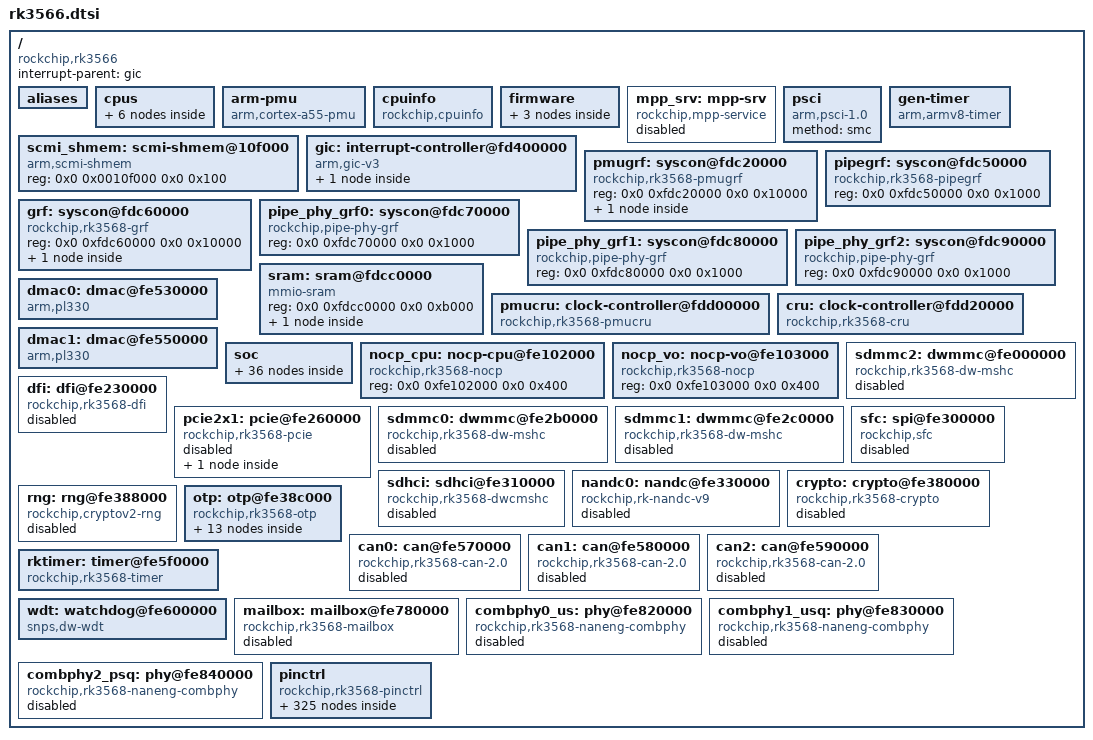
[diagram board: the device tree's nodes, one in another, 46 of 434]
/**
 * Copyright (c) 2019 PT Switch.
 * All rights reserved.
 *
 * This program is free software; you can redistribute it and/or modify
 * it under the terms of the GNU General Public License as published by
 * the Free Software Foundation; either version 2, or (at your option)
 * any later version.
 *
 * This program is distributed in the hope that it will be useful,
 * but WITHOUT ANY WARRANTY; without even the implied warranty of
 * MERCHANTABILITY or FITNESS FOR A PARTICULAR PURPOSE.  See the
 * GNU General Public License for more details.
 *
 * You should have received a copy of the GNU General Public License
 * along with this program; if not, write to the Free Software
 * Foundation, Inc., 675 Mass Ave, Cambridge, MA 02139, USA.
 *
 * @file rk3566.dtsi
 * @author
 * @brief RK3566 SOC device tree
 */

#include <dt-bindings/clock/rk3568-cru.h>
#include <dt-bindings/interrupt-controller/arm-gic.h>
#include <dt-bindings/interrupt-controller/irq.h>
#include <dt-bindings/pinctrl/rockchip.h>
#include <dt-bindings/phy/phy.h>

/ {
	compatible = "rockchip,rk3566";
	interrupt-parent = <&gic>;
	#address-cells = <2>;
	#size-cells = <2>;

    aliases {  };

	cpus {
		#address-cells = <2>;
		#size-cells = <0>;

		cpu@0 {
			device_type = "cpu";
			compatible = "arm,cortex-a55";
			reg = <0>;
			enable-method = "psci";
			clocks = <&scmi_clk 0>;
			cpu-idle-states = <&CPU_SLEEP>;
			#cooling-cells = <2>;
		};

		cpu@1 {
			device_type = "cpu";
			compatible = "arm,cortex-a55";
			reg = <1>;
			enable-method = "psci";
			clocks = <&scmi_clk 0>;
			cpu-idle-states = <&CPU_SLEEP>;
		};

		cpu@2 {
			device_type = "cpu";
			compatible = "arm,cortex-a55";
			reg = <2>;
			enable-method = "psci";
			clocks = <&scmi_clk 0>;
			cpu-idle-states = <&CPU_SLEEP>;
		};

		cpu@3 {
			device_type = "cpu";
			compatible = "arm,cortex-a55";
			reg = <3>;
			enable-method = "psci";
			clocks = <&scmi_clk 0>;
			cpu-idle-states = <&CPU_SLEEP>;
		};

		idle-states {
			entry-method = "psci";
			CPU_SLEEP: cpu-sleep {
				compatible = "arm,idle-state";
				local-timer-stop;
				arm,psci-suspend-param = <0x0010000>;
				entry-latency-us = <100>;
				exit-latency-us = <120>;
				min-residency-us = <1000>;
			};
		};
	};

	arm-pmu {
		compatible = "arm,cortex-a55-pmu", "arm,armv8-pmuv3";
		interrupts = <GIC_SPI 228 IRQ_TYPE_LEVEL_HIGH>,
			     <GIC_SPI 229 IRQ_TYPE_LEVEL_HIGH>,
			     <GIC_SPI 230 IRQ_TYPE_LEVEL_HIGH>,
			     <GIC_SPI 231 IRQ_TYPE_LEVEL_HIGH>;
		// interrupt-affinity = <&cpu0>, <&cpu1>, <&cpu2>, <&cpu3>;
	};

	cpuinfo {
		compatible = "rockchip,cpuinfo";
		nvmem-cells = <&otp_id>, <&otp_cpu_version>, <&cpu_code>, <&performance>;
		nvmem-cell-names = "id", "cpu-version", "cpu-code", "performance";
	};

	firmware {
		scmi: scmi {
			compatible = "arm,scmi-smc";
			shmem = <&scmi_shmem>;
			arm,smc-id = <0x82000010>;
			#address-cells = <1>;
			#size-cells = <0>;

			scmi_clk: protocol@14 {
				reg = <0x14>;
				#clock-cells = <1>;

				rockchip,clk-init = <1104000000>;
			};
		};

		sdei: sdei {
			compatible = "arm,sdei-1.0";
			method = "smc";
		};
	};

	mpp_srv: mpp-srv {
		compatible = "rockchip,mpp-service";
		rockchip,taskqueue-count = <6>;
		rockchip,resetgroup-count = <6>;
		status = "disabled";
	};

	psci {
		compatible = "arm,psci-1.0";
		method = "smc";
	};

	gen-timer {
		compatible = "arm,armv8-timer";
		interrupts = <GIC_PPI 13 (GIC_CPU_MASK_SIMPLE(4) | IRQ_TYPE_LEVEL_HIGH)>,
			     <GIC_PPI 14 (GIC_CPU_MASK_SIMPLE(4) | IRQ_TYPE_LEVEL_HIGH)>,
			     <GIC_PPI 11 (GIC_CPU_MASK_SIMPLE(4) | IRQ_TYPE_LEVEL_HIGH)>,
			     <GIC_PPI 10 (GIC_CPU_MASK_SIMPLE(4) | IRQ_TYPE_LEVEL_HIGH)>;
		arm,no-tick-in-suspend;
	};

	scmi_shmem: scmi-shmem@10f000 {
		compatible = "arm,scmi-shmem";
		reg = <0x0 0x0010f000 0x0 0x100>;
	};

	gic: interrupt-controller@fd400000 {
		compatible = "arm,gic-v3";
		#interrupt-cells = <3>;
		#address-cells = <2>;
		#size-cells = <2>;
		ranges;
		interrupt-controller;

		reg = <0x0 0xfd400000 0 0x10000>, /* GICD */
		      <0x0 0xfd460000 0 0xc0000>; /* GICR */
		interrupts = <GIC_PPI 9 IRQ_TYPE_LEVEL_HIGH>;
		its: interrupt-controller@fd440000 {
			compatible = "arm,gic-v3-its";
			msi-controller;
			#msi-cells = <1>;
			reg = <0x0 0xfd440000 0x0 0x20000>;
		};
	};

	pmugrf: syscon@fdc20000 {
		compatible = "rockchip,rk3568-pmugrf", "syscon", "simple-mfd";
		reg = <0x0 0xfdc20000 0x0 0x10000>;

		pmu_io_domains: io-domains {
			compatible = "rockchip,rk3568-pmu-io-voltage-domain";
			status = "disabled";
		};

        #if 0
		reboot_mode: reboot-mode {
			compatible = "syscon-reboot-mode";
			offset = <0x200>;
			mode-bootloader = <BOOT_BL_DOWNLOAD>;
			mode-charge = <BOOT_CHARGING>;
			mode-fastboot = <BOOT_FASTBOOT>;
			mode-loader = <BOOT_BL_DOWNLOAD>;
			mode-normal = <BOOT_NORMAL>;
			mode-recovery = <BOOT_RECOVERY>;
			mode-ums = <BOOT_UMS>;
			mode-panic = <BOOT_PANIC>;
			mode-watchdog = <BOOT_WATCHDOG>;
		};
        #endif
	};

	pipegrf: syscon@fdc50000 {
		compatible = "rockchip,rk3568-pipegrf", "syscon";
		reg = <0x0 0xfdc50000 0x0 0x1000>;
	};

	grf: syscon@fdc60000 {
		compatible = "rockchip,rk3568-grf", "syscon", "simple-mfd";
		reg = <0x0 0xfdc60000 0x0 0x10000>;

		io_domains: io-domains {
			compatible = "rockchip,rk3568-io-voltage-domain";
			status = "disabled";
		};
	};

	pipe_phy_grf0: syscon@fdc70000 {
		compatible = "rockchip,pipe-phy-grf", "syscon";
		reg = <0x0 0xfdc70000 0x0 0x1000>;
	};

	pipe_phy_grf1: syscon@fdc80000 {
		compatible = "rockchip,pipe-phy-grf", "syscon";
		reg = <0x0 0xfdc80000 0x0 0x1000>;
	};

	pipe_phy_grf2: syscon@fdc90000 {
		compatible = "rockchip,pipe-phy-grf", "syscon";
		reg = <0x0 0xfdc90000 0x0 0x1000>;
	};

	sram: sram@fdcc0000 {
		compatible = "mmio-sram";
		reg = <0x0 0xfdcc0000 0x0 0xb000>;

		#address-cells = <1>;
		#size-cells = <1>;
		ranges = <0x0 0x0 0xfdcc0000 0xb000>;

		/* start address and size should be 4k algin */
		rkvdec_sram: rkvdec-sram@0 {
			reg = <0x0 0xb000>;
		};
	};

	pmucru: clock-controller@fdd00000 {
		compatible = "rockchip,rk3568-pmucru";
		reg = <0x0 0xfdd00000 0x0 0x1000>;
		rockchip,grf = <&grf>;
		rockchip,pmugrf = <&pmugrf>;
		#clock-cells = <1>;
		#reset-cells = <1>;

		assigned-clocks = <&pmucru SCLK_32K_IOE>;
		assigned-clock-parents = <&pmucru CLK_RTC_32K>;
	};

	cru: clock-controller@fdd20000 {
		compatible = "rockchip,rk3568-cru";
		reg = <0x0 0xfdd20000 0x0 0x1000>;
		rockchip,grf = <&grf>;
		#clock-cells = <1>;
		#reset-cells = <1>;

		assigned-clocks =
			<&pmucru CLK_RTC_32K>, <&cru ACLK_RKVDEC_PRE>,
			<&cru CLK_RKVDEC_CORE>, <&pmucru PLL_PPLL>,
			<&pmucru PCLK_PMU>, <&cru PLL_CPLL>,
			<&cru CPLL_500M>, <&cru CPLL_333M>,
			<&cru CPLL_250M>, <&cru CPLL_125M>,
			<&cru CPLL_100M>, <&cru CPLL_62P5M>,
			<&cru CPLL_50M>, <&cru CPLL_25M>,
			<&cru PLL_GPLL>,
			<&cru ACLK_BUS>, <&cru PCLK_BUS>,
			<&cru ACLK_TOP_HIGH>, <&cru ACLK_TOP_LOW>,
			<&cru HCLK_TOP>, <&cru PCLK_TOP>,
			<&cru ACLK_PERIMID>, <&cru HCLK_PERIMID>,
			<&cru PLL_NPLL>, <&cru ACLK_PIPE>,
			<&cru PCLK_PIPE>, <&cru CLK_I2S0_8CH_TX_SRC>,
			<&cru CLK_I2S0_8CH_RX_SRC>, <&cru CLK_I2S1_8CH_TX_SRC>,
			<&cru CLK_I2S1_8CH_RX_SRC>, <&cru CLK_I2S2_2CH_SRC>,
			<&cru CLK_I2S2_2CH_SRC>, <&cru CLK_I2S3_2CH_RX_SRC>,
			<&cru CLK_I2S3_2CH_TX_SRC>, <&cru MCLK_SPDIF_8CH_SRC>,
			<&cru ACLK_VOP>;
		assigned-clock-rates =
			<32768>, <300000000>,
			<300000000>, <200000000>,
			<100000000>, <1000000000>,
			<500000000>, <333000000>,
			<250000000>, <125000000>,
			<100000000>, <62500000>,
			<50000000>, <25000000>,
			<1188000000>,
			<150000000>, <100000000>,
			<500000000>, <400000000>,
			<150000000>, <100000000>,
			<300000000>, <150000000>,
			<1200000000>, <400000000>,
			<100000000>, <1188000000>,
			<1188000000>, <1188000000>,
			<1188000000>, <1188000000>,
			<1188000000>, <1188000000>,
			<1188000000>, <1188000000>,
			<500000000>;
		assigned-clock-parents =
			<&pmucru CLK_RTC32K_FRAC>, <&cru PLL_GPLL>,
			<&cru PLL_GPLL>;
	};

	dmac0: dmac@fe530000 {
		compatible = "arm,pl330", "arm,primecell";
		reg = <0x0 0xfe530000 0x0 0x4000>;
		interrupts = <GIC_SPI 14 IRQ_TYPE_LEVEL_HIGH>,
			     <GIC_SPI 13 IRQ_TYPE_LEVEL_HIGH>;
		clocks = <&cru ACLK_BUS>;
		clock-names = "apb_pclk";
		#dma-cells = <1>;
		arm,pl330-periph-burst;
	};

	dmac1: dmac@fe550000 {
		compatible = "arm,pl330", "arm,primecell";
		reg = <0x0 0xfe550000 0x0 0x4000>;
		interrupts = <GIC_SPI 16 IRQ_TYPE_LEVEL_HIGH>,
			     <GIC_SPI 15 IRQ_TYPE_LEVEL_HIGH>;
		clocks = <&cru ACLK_BUS>;
		clock-names = "apb_pclk";
		#dma-cells = <1>;
		arm,pl330-periph-burst;
	};

    soc: soc {
        i2c0: i2c@fdd40000 {
            compatible = "rockchip,rk3399-i2c";
            reg = <0x0 0xfdd40000 0x0 0x1000>;
            clocks = <&pmucru CLK_I2C0>, <&pmucru PCLK_I2C0>;
            clock-names = "i2c", "pclk";
            interrupts = <GIC_SPI 46 IRQ_TYPE_LEVEL_HIGH>;
            pinctrl-names = "default";
            pinctrl-0 = <&i2c0_xfer>;
            #address-cells = <1>;
            #size-cells = <0>;
            status = "disabled";
        };

        i2c1: i2c@fe5a0000 {
            compatible = "rockchip,rk3399-i2c";
            reg = <0x0 0xfe5a0000 0x0 0x1000>;
            clocks = <&cru CLK_I2C1>, <&cru PCLK_I2C1>;
            clock-names = "i2c", "pclk";
            interrupts = <GIC_SPI 47 IRQ_TYPE_LEVEL_HIGH>;
            pinctrl-names = "default";
            pinctrl-0 = <&i2c1_xfer>;
            #address-cells = <1>;
            #size-cells = <0>;
            status = "disabled";
        };

        i2c2: i2c@fe5b0000 {
            compatible = "rockchip,rk3399-i2c";
            reg = <0x0 0xfe5b0000 0x0 0x1000>;
            clocks = <&cru CLK_I2C2>, <&cru PCLK_I2C2>;
            clock-names = "i2c", "pclk";
            interrupts = <GIC_SPI 48 IRQ_TYPE_LEVEL_HIGH>;
            pinctrl-names = "default";
            pinctrl-0 = <&i2c2m0_xfer>;
            #address-cells = <1>;
            #size-cells = <0>;
            status = "disabled";
        };

        i2c3: i2c@fe5c0000 {
            compatible = "rockchip,rk3399-i2c";
            reg = <0x0 0xfe5c0000 0x0 0x1000>;
            clocks = <&cru CLK_I2C3>, <&cru PCLK_I2C3>;
            clock-names = "i2c", "pclk";
            interrupts = <GIC_SPI 49 IRQ_TYPE_LEVEL_HIGH>;
            pinctrl-names = "default";
            pinctrl-0 = <&i2c3m0_xfer>;
            #address-cells = <1>;
            #size-cells = <0>;
            status = "disabled";
        };

        i2c4: i2c@fe5d0000 {
            compatible = "rockchip,rk3399-i2c";
            reg = <0x0 0xfe5d0000 0x0 0x1000>;
            clocks = <&cru CLK_I2C4>, <&cru PCLK_I2C4>;
            clock-names = "i2c", "pclk";
            interrupts = <GIC_SPI 50 IRQ_TYPE_LEVEL_HIGH>;
            pinctrl-names = "default";
            pinctrl-0 = <&i2c4m0_xfer>;
            #address-cells = <1>;
            #size-cells = <0>;
            status = "disabled";
        };

        i2c5: i2c@fe5e0000 {
            compatible = "rockchip,rk3399-i2c";
            reg = <0x0 0xfe5e0000 0x0 0x1000>;
            clocks = <&cru CLK_I2C5>, <&cru PCLK_I2C5>;
            clock-names = "i2c", "pclk";
            interrupts = <GIC_SPI 51 IRQ_TYPE_LEVEL_HIGH>;
            pinctrl-names = "default";
            pinctrl-0 = <&i2c5m0_xfer>;
            #address-cells = <1>;
            #size-cells = <0>;
            status = "disabled";
        };
        /* fdd50000 */
        SERIAL0: uart0 {
            compatible = "rockchip,rk3568-uart", "snps,dw-apb-uart";
            reg = <0x0 0xfdd50000 0x0 0x100>;
            interrupts = <GIC_SPI 116 IRQ_TYPE_LEVEL_HIGH>;
            clocks = <&pmucru SCLK_UART0>, <&pmucru PCLK_UART0>;
            clock-names = "baudclk", "apb_pclk";
            reg-shift = <2>;
            reg-io-width = <4>;
            dmas = <&dmac0 0>, <&dmac0 1>;
            pinctrl-names = "default";
            pinctrl-0 = <&uart0_xfer>;
            status = "disabled";
        };
        /* fe650000 */
        SERIAL1: uart1 {
            compatible = "rockchip,rk3568-uart", "snps,dw-apb-uart";
            reg = <0x0 0xfe650000 0x0 0x100>;
            interrupts = <GIC_SPI 117 IRQ_TYPE_LEVEL_HIGH>;
            clocks = <&cru SCLK_UART1>, <&cru PCLK_UART1>;
            clock-names = "baudclk", "apb_pclk";
            reg-shift = <2>;
            reg-io-width = <4>;
            dmas = <&dmac0 2>, <&dmac0 3>;
            pinctrl-names = "default";
            pinctrl-0 = <&uart1m0_xfer>;
            status = "disabled";
        };

        /* fe660000 */
        SERIAL2: uart2 {
            compatible = "snps,dw-apb-uart";
            reg = <0x0 0xfe660000 0x0 0x100>;
            interrupts = <GIC_SPI 118 IRQ_TYPE_LEVEL_HIGH>;
            clocks = <&cru SCLK_UART2>, <&cru PCLK_UART2>;
            clock-names = "baudclk", "apb_pclk";
            reg-shift = <2>;
            reg-io-width = <4>;
            dmas = <&dmac0 4>, <&dmac0 5>;
            pinctrl-names = "debug-serial";
            pinctrl-0 = <&uart2m0_xfer>;
            status = "okay";
        };
        /* fe670000 */
        SERIAL3: uart3 {
            compatible = "rockchip,rk3568-uart", "snps,dw-apb-uart";
            reg = <0x0 0xfe670000 0x0 0x100>;
            interrupts = <GIC_SPI 119 IRQ_TYPE_LEVEL_HIGH>;
            clocks = <&cru SCLK_UART3>, <&cru PCLK_UART3>;
            clock-names = "baudclk", "apb_pclk";
            reg-shift = <2>;
            reg-io-width = <4>;
            dmas = <&dmac0 6>, <&dmac0 7>;
            pinctrl-names = "default";
            pinctrl-0 = <&uart3m0_xfer>;
            status = "disabled";
        };
        /* fe680000 */
        SERIAL4: uart4 {
            compatible = "rockchip,rk3568-uart", "snps,dw-apb-uart";
            reg = <0x0 0xfe680000 0x0 0x100>;
            interrupts = <GIC_SPI 120 IRQ_TYPE_LEVEL_HIGH>;
            clocks = <&cru SCLK_UART4>, <&cru PCLK_UART4>;
            clock-names = "baudclk", "apb_pclk";
            reg-shift = <2>;
            reg-io-width = <4>;
            dmas = <&dmac0 8>, <&dmac0 9>;
            pinctrl-names = "default";
            pinctrl-0 = <&uart4m0_xfer>;
            status = "disabled";
        };
        /* fe690000 */
        SERIAL5: uart5 {
            compatible = "rockchip,rk3568-uart", "snps,dw-apb-uart";
            reg = <0x0 0xfe690000 0x0 0x100>;
            interrupts = <GIC_SPI 121 IRQ_TYPE_LEVEL_HIGH>;
            clocks = <&cru SCLK_UART5>, <&cru PCLK_UART5>;
            clock-names = "baudclk", "apb_pclk";
            reg-shift = <2>;
            reg-io-width = <4>;
            dmas = <&dmac0 10>, <&dmac0 11>;
            pinctrl-names = "default";
            pinctrl-0 = <&uart5m0_xfer>;
            status = "disabled";
        };
        /* fe6a0000 */
        SERIAL6: uart6 {
            compatible = "rockchip,rk3568-uart", "snps,dw-apb-uart";
            reg = <0x0 0xfe6a0000 0x0 0x100>;
            interrupts = <GIC_SPI 122 IRQ_TYPE_LEVEL_HIGH>;
            clocks = <&cru SCLK_UART6>, <&cru PCLK_UART6>;
            clock-names = "baudclk", "apb_pclk";
            reg-shift = <2>;
            reg-io-width = <4>;
            dmas = <&dmac0 12>, <&dmac0 13>;
            pinctrl-names = "default";
            pinctrl-0 = <&uart6m0_xfer>;
            status = "disabled";
        };
        /* fe6b0000 */
        SERIAL7: uart7 {
            compatible = "rockchip,rk3568-uart", "snps,dw-apb-uart";
            reg = <0x0 0xfe6b0000 0x0 0x100>;
            interrupts = <GIC_SPI 123 IRQ_TYPE_LEVEL_HIGH>;
            clocks = <&cru SCLK_UART7>, <&cru PCLK_UART7>;
            clock-names = "baudclk", "apb_pclk";
            reg-shift = <2>;
            reg-io-width = <4>;
            dmas = <&dmac0 14>, <&dmac0 15>;
            pinctrl-names = "default";
            pinctrl-0 = <&uart7m0_xfer>;
            status = "disabled";
        };
        /* fe6c0000 */
        SERIAL8: uart8 {
            compatible = "rockchip,rk3568-uart", "snps,dw-apb-uart";
            reg = <0x0 0xfe6c0000 0x0 0x100>;
            interrupts = <GIC_SPI 124 IRQ_TYPE_LEVEL_HIGH>;
            clocks = <&cru SCLK_UART8>, <&cru PCLK_UART8>;
            clock-names = "baudclk", "apb_pclk";
            reg-shift = <2>;
            reg-io-width = <4>;
            dmas = <&dmac0 16>, <&dmac0 17>;
            pinctrl-names = "default";
            pinctrl-0 = <&uart8m0_xfer>;
            status = "disabled";
        };
        /* fe6d0000 */
        SERIAL9: uart9 {
            compatible = "rockchip,rk3568-uart", "snps,dw-apb-uart";
            reg = <0x0 0xfe6d0000 0x0 0x100>;
            interrupts = <GIC_SPI 125 IRQ_TYPE_LEVEL_HIGH>;
            clocks = <&cru SCLK_UART9>, <&cru PCLK_UART9>;
            clock-names = "baudclk", "apb_pclk";
            reg-shift = <2>;
            reg-io-width = <4>;
            dmas = <&dmac0 18>, <&dmac0 19>;
            pinctrl-names = "default";
            pinctrl-0 = <&uart9m0_xfer>;
            status = "disabled";
        };

        spi0: spi@fe610000 {
            compatible = "rockchip,rk3066-spi";
            reg = <0x0 0xfe610000 0x0 0x1000>;
            interrupts = <GIC_SPI 103 IRQ_TYPE_LEVEL_HIGH>;
            #address-cells = <1>;
            #size-cells = <0>;
            clocks = <&cru CLK_SPI0>, <&cru PCLK_SPI0>;
            clock-names = "spiclk", "apb_pclk";
            dmas = <&dmac0 20>, <&dmac0 21>;
            dma-names = "tx", "rx";
            pinctrl-names = "default", "high_speed";
            pinctrl-0 = <&spi0m0_cs0 &spi0m0_cs1 &spi0m0_pins>;
            pinctrl-1 = <&spi0m0_cs0 &spi0m0_cs1 &spi0m0_pins_hs>;
            num-cs = <2>;
            status = "disabled";
        };

        spi1: spi@fe620000 {
            compatible = "rockchip,rk3066-spi";
            reg = <0x0 0xfe620000 0x0 0x1000>;
            interrupts = <GIC_SPI 104 IRQ_TYPE_LEVEL_HIGH>;
            #address-cells = <1>;
            #size-cells = <0>;
            clocks = <&cru CLK_SPI1>, <&cru PCLK_SPI1>;
            clock-names = "spiclk", "apb_pclk";
            dmas = <&dmac0 22>, <&dmac0 23>;
            dma-names = "tx", "rx";
            pinctrl-names = "default", "high_speed";
            pinctrl-0 = <&spi1m0_cs0 &spi1m0_cs1 &spi1m0_pins>;
            pinctrl-1 = <&spi1m0_cs0 &spi1m0_cs1 &spi1m0_pins_hs>;
            num-cs = <2>;
            status = "disabled";
        };

        spi2: spi@fe630000 {
            compatible = "rockchip,rk3066-spi";
            reg = <0x0 0xfe630000 0x0 0x1000>;
            interrupts = <GIC_SPI 105 IRQ_TYPE_LEVEL_HIGH>;
            #address-cells = <1>;
            #size-cells = <0>;
            clocks = <&cru CLK_SPI2>, <&cru PCLK_SPI2>;
            clock-names = "spiclk", "apb_pclk";
            dmas = <&dmac0 24>, <&dmac0 25>;
            dma-names = "tx", "rx";
            pinctrl-names = "default", "high_speed";
            pinctrl-0 = <&spi2m0_cs0 &spi2m0_cs1 &spi2m0_pins>;
            pinctrl-1 = <&spi2m0_cs0 &spi2m0_cs1 &spi2m0_pins_hs>;
            num-cs = <2>;
            status = "disabled";
        };

        spi3: spi@fe640000 {
            compatible = "rockchip,rk3066-spi";
            reg = <0x0 0xfe640000 0x0 0x1000>;
            interrupts = <GIC_SPI 106 IRQ_TYPE_LEVEL_HIGH>;
            #address-cells = <1>;
            #size-cells = <0>;
            clocks = <&cru CLK_SPI3>, <&cru PCLK_SPI3>;
            clock-names = "spiclk", "apb_pclk";
            dmas = <&dmac0 26>, <&dmac0 27>;
            dma-names = "tx", "rx";
            pinctrl-names = "default", "high_speed";
            pinctrl-0 = <&spi3m0_cs0 &spi3m0_cs1 &spi3m0_pins>;
            pinctrl-1 = <&spi3m0_cs0 &spi3m0_cs1 &spi3m0_pins_hs>;
            num-cs = <2>;
            status = "disabled";
        };

        pwm0: pwm@fdd70000 {
            compatible = "rockchip,rk3568-pwm", "rockchip,rk3328-pwm";
            reg = <0x0 0xfdd70000 0x0 0x10>;
            #pwm-cells = <3>;
            pinctrl-names = "active";
            pinctrl-0 = <&pwm0m0_pins>;
            clocks = <&pmucru CLK_PWM0>, <&pmucru PCLK_PWM0>;
            clock-names = "pwm", "pclk";
            status = "disabled";
        };

        pwm1: pwm@fdd70010 {
            compatible = "rockchip,rk3568-pwm", "rockchip,rk3328-pwm";
            reg = <0x0 0xfdd70010 0x0 0x10>;
            #pwm-cells = <3>;
            pinctrl-names = "active";
            pinctrl-0 = <&pwm1m0_pins>;
            clocks = <&pmucru CLK_PWM0>, <&pmucru PCLK_PWM0>;
            clock-names = "pwm", "pclk";
            status = "disabled";
        };

        pwm2: pwm@fdd70020 {
            compatible = "rockchip,rk3568-pwm", "rockchip,rk3328-pwm";
            reg = <0x0 0xfdd70020 0x0 0x10>;
            #pwm-cells = <3>;
            pinctrl-names = "active";
            pinctrl-0 = <&pwm2m0_pins>;
            clocks = <&pmucru CLK_PWM0>, <&pmucru PCLK_PWM0>;
            clock-names = "pwm", "pclk";
            status = "disabled";
        };

        pwm3: pwm@fdd70030 {
            compatible = "rockchip,rk3568-pwm", "rockchip,rk3328-pwm";
            reg = <0x0 0xfdd70030 0x0 0x10>;
            interrupts = <GIC_SPI 82 IRQ_TYPE_LEVEL_HIGH>,
                     <GIC_SPI 86 IRQ_TYPE_LEVEL_HIGH>;
            #pwm-cells = <3>;
            pinctrl-names = "active";
            pinctrl-0 = <&pwm3_pins>;
            clocks = <&pmucru CLK_PWM0>, <&pmucru PCLK_PWM0>;
            clock-names = "pwm", "pclk";
            status = "disabled";
        };

        pwm4: pwm@fe6e0000 {
            compatible = "rockchip,rk3568-pwm", "rockchip,rk3328-pwm";
            reg = <0x0 0xfe6e0000 0x0 0x10>;
            #pwm-cells = <3>;
            pinctrl-names = "active";
            pinctrl-0 = <&pwm4_pins>;
            clocks = <&cru CLK_PWM1>, <&cru PCLK_PWM1>;
            clock-names = "pwm", "pclk";
            status = "disabled";
        };

        pwm5: pwm@fe6e0010 {
            compatible = "rockchip,rk3568-pwm", "rockchip,rk3328-pwm";
            reg = <0x0 0xfe6e0010 0x0 0x10>;
            #pwm-cells = <3>;
            pinctrl-names = "active";
            pinctrl-0 = <&pwm5_pins>;
            clocks = <&cru CLK_PWM1>, <&cru PCLK_PWM1>;
            clock-names = "pwm", "pclk";
            status = "disabled";
        };

        pwm6: pwm@fe6e0020 {
            compatible = "rockchip,rk3568-pwm", "rockchip,rk3328-pwm";
            reg = <0x0 0xfe6e0020 0x0 0x10>;
            #pwm-cells = <3>;
            pinctrl-names = "active";
            pinctrl-0 = <&pwm6_pins>;
            clocks = <&cru CLK_PWM1>, <&cru PCLK_PWM1>;
            clock-names = "pwm", "pclk";
            status = "disabled";
        };

        pwm7: pwm@fe6e0030 {
            compatible = "rockchip,rk3568-pwm", "rockchip,rk3328-pwm";
            reg = <0x0 0xfe6e0030 0x0 0x10>;
            interrupts = <GIC_SPI 83 IRQ_TYPE_LEVEL_HIGH>,
                     <GIC_SPI 87 IRQ_TYPE_LEVEL_HIGH>;
            #pwm-cells = <3>;
            pinctrl-names = "active";
            pinctrl-0 = <&pwm7_pins>;
            clocks = <&cru CLK_PWM1>, <&cru PCLK_PWM1>;
            clock-names = "pwm", "pclk";
            status = "disabled";
        };

        pwm8: pwm@fe6f0000 {
            compatible = "rockchip,rk3568-pwm", "rockchip,rk3328-pwm";
            reg = <0x0 0xfe6f0000 0x0 0x10>;
            #pwm-cells = <3>;
            pinctrl-names = "active";
            pinctrl-0 = <&pwm8m0_pins>;
            clocks = <&cru CLK_PWM2>, <&cru PCLK_PWM2>;
            clock-names = "pwm", "pclk";
            status = "disabled";
        };

        pwm9: pwm@fe6f0010 {
            compatible = "rockchip,rk3568-pwm", "rockchip,rk3328-pwm";
            reg = <0x0 0xfe6f0010 0x0 0x10>;
            #pwm-cells = <3>;
            pinctrl-names = "active";
            pinctrl-0 = <&pwm9m0_pins>;
            clocks = <&cru CLK_PWM2>, <&cru PCLK_PWM2>;
            clock-names = "pwm", "pclk";
            status = "disabled";
        };

        pwm10: pwm@fe6f0020 {
            compatible = "rockchip,rk3568-pwm", "rockchip,rk3328-pwm";
            reg = <0x0 0xfe6f0020 0x0 0x10>;
            #pwm-cells = <3>;
            pinctrl-names = "active";
            pinctrl-0 = <&pwm10m0_pins>;
            clocks = <&cru CLK_PWM2>, <&cru PCLK_PWM2>;
            clock-names = "pwm", "pclk";
            status = "disabled";
        };

        pwm11: pwm@fe6f0030 {
            compatible = "rockchip,rk3568-pwm", "rockchip,rk3328-pwm";
            reg = <0x0 0xfe6f0030 0x0 0x10>;
            interrupts = <GIC_SPI 84 IRQ_TYPE_LEVEL_HIGH>,
                     <GIC_SPI 88 IRQ_TYPE_LEVEL_HIGH>;
            #pwm-cells = <3>;
            pinctrl-names = "active";
            pinctrl-0 = <&pwm11m0_pins>;
            clocks = <&cru CLK_PWM2>, <&cru PCLK_PWM2>;
            clock-names = "pwm", "pclk";
            status = "disabled";
        };

        pwm12: pwm@fe700000 {
            compatible = "rockchip,rk3568-pwm", "rockchip,rk3328-pwm";
            reg = <0x0 0xfe700000 0x0 0x10>;
            #pwm-cells = <3>;
            pinctrl-names = "active";
            pinctrl-0 = <&pwm12m0_pins>;
            clocks = <&cru CLK_PWM3>, <&cru PCLK_PWM3>;
            clock-names = "pwm", "pclk";
            status = "disabled";
        };

        pwm13: pwm@fe700010 {
            compatible = "rockchip,rk3568-pwm", "rockchip,rk3328-pwm";
            reg = <0x0 0xfe700010 0x0 0x10>;
            #pwm-cells = <3>;
            pinctrl-names = "active";
            pinctrl-0 = <&pwm13m0_pins>;
            clocks = <&cru CLK_PWM3>, <&cru PCLK_PWM3>;
            clock-names = "pwm", "pclk";
            status = "disabled";
        };

        pwm14: pwm@fe700020 {
            compatible = "rockchip,rk3568-pwm", "rockchip,rk3328-pwm";
            reg = <0x0 0xfe700020 0x0 0x10>;
            #pwm-cells = <3>;
            pinctrl-names = "active";
            pinctrl-0 = <&pwm14m0_pins>;
            clocks = <&cru CLK_PWM3>, <&cru PCLK_PWM3>;
            clock-names = "pwm", "pclk";
            status = "disabled";
        };

        pwm15: pwm@fe700030 {
            compatible = "rockchip,rk3568-pwm", "rockchip,rk3328-pwm";
            reg = <0x0 0xfe700030 0x0 0x10>;
            interrupts = <GIC_SPI 85 IRQ_TYPE_LEVEL_HIGH>,
                     <GIC_SPI 89 IRQ_TYPE_LEVEL_HIGH>;
            #pwm-cells = <3>;
            pinctrl-names = "active";
            pinctrl-0 = <&pwm15m0_pins>;
            clocks = <&cru CLK_PWM3>, <&cru PCLK_PWM3>;
            clock-names = "pwm", "pclk";
            status = "disabled";
        };
    };

	nocp_cpu: nocp-cpu@fe102000 {
		compatible = "rockchip,rk3568-nocp";
		reg = <0x0 0xfe102000 0x0 0x400>;
	};

	nocp_vo: nocp-vo@fe103000 {
		compatible = "rockchip,rk3568-nocp";
		reg = <0x0 0xfe103000 0x0 0x400>;
	};

	sdmmc2: dwmmc@fe000000 {
		compatible = "rockchip,rk3568-dw-mshc",
			     "rockchip,rk3288-dw-mshc";
		reg = <0x0 0xfe000000 0x0 0x4000>;
		interrupts = <GIC_SPI 100 IRQ_TYPE_LEVEL_HIGH>;
		max-frequency = <150000000>;
		clocks = <&cru HCLK_SDMMC2>, <&cru CLK_SDMMC2>,
			 <&cru SCLK_SDMMC2_DRV>, <&cru SCLK_SDMMC2_SAMPLE>;
		clock-names = "biu", "ciu", "ciu-drive", "ciu-sample";
		fifo-depth = <0x100>;
		resets = <&cru SRST_SDMMC2>;
		reset-names = "reset";
		status = "disabled";
	};

	dfi: dfi@fe230000 {
		reg = <0x00 0xfe230000 0x00 0x400>;
		compatible = "rockchip,rk3568-dfi";
		rockchip,pmugrf = <&pmugrf>;
		status = "disabled";
	};

	pcie2x1: pcie@fe260000 {
		compatible = "rockchip,rk3568-pcie", "snps,dw-pcie";
		#address-cells = <3>;
		#size-cells = <2>;
		bus-range = <0x0 0xf>;
		clocks = <&cru ACLK_PCIE20_MST>, <&cru ACLK_PCIE20_SLV>,
			 <&cru ACLK_PCIE20_DBI>, <&cru PCLK_PCIE20>,
			 <&cru CLK_PCIE20_AUX_NDFT>;
		clock-names = "aclk_mst", "aclk_slv",
			      "aclk_dbi", "pclk", "aux";
		device_type = "pci";
		interrupts = <GIC_SPI 75 IRQ_TYPE_LEVEL_HIGH>,
			     <GIC_SPI 74 IRQ_TYPE_LEVEL_HIGH>,
			     <GIC_SPI 73 IRQ_TYPE_LEVEL_HIGH>,
			     <GIC_SPI 72 IRQ_TYPE_LEVEL_HIGH>,
			     <GIC_SPI 71 IRQ_TYPE_LEVEL_HIGH>;
		interrupt-names = "sys", "pmc", "msg", "legacy", "err";
		#interrupt-cells = <1>;
		interrupt-map-mask = <0 0 0 7>;
		interrupt-map = <0 0 0 1 &pcie2x1_intc 0>,
				<0 0 0 2 &pcie2x1_intc 1>,
				<0 0 0 3 &pcie2x1_intc 2>,
				<0 0 0 4 &pcie2x1_intc 3>;
		linux,pci-domain = <0>;
		num-ib-windows = <6>;
		num-viewport = <8>;
		num-ob-windows = <2>;
		max-link-speed = <2>;
		msi-map = <0x0 &its 0x0 0x1000>;
		num-lanes = <1>;
		phys = <&combphy2_psq PHY_TYPE_PCIE>;
		phy-names = "pcie-phy";
		// power-domains = <&power RK3568_PD_PIPE>;
		ranges = <0x00000800 0x0 0xf4000000 0x0 0xf4000000 0x0 0x100000
			  0x81000000 0x0 0xf4100000 0x0 0xf4100000 0x0 0x100000
			  0x82000000 0x0 0xf4200000 0x0 0xf4200000 0x0 0x1e00000
			  0xc3000000 0x3 0x00000000 0x3 0x00000000 0x0 0x40000000>;
		reg = <0x3 0xc0000000 0x0 0x400000>,
		      <0x0 0xfe260000 0x0 0x10000>;
		reg-names = "pcie-dbi", "pcie-apb";
		resets = <&cru SRST_PCIE20_POWERUP>;
		reset-names = "pipe";
		status = "disabled";

		pcie2x1_intc: legacy-interrupt-controller {
			interrupt-controller;
			#address-cells = <0>;
			#interrupt-cells = <1>;
			interrupt-parent = <&gic>;
			interrupts = <GIC_SPI 72 IRQ_TYPE_EDGE_RISING>;
		};
	};

	sdmmc0: dwmmc@fe2b0000 {
		compatible = "rockchip,rk3568-dw-mshc",
			     "rockchip,rk3288-dw-mshc";
		reg = <0x0 0xfe2b0000 0x0 0x4000>;
		interrupts = <GIC_SPI 98 IRQ_TYPE_LEVEL_HIGH>;
		max-frequency = <150000000>;
		clocks = <&cru HCLK_SDMMC0>, <&cru CLK_SDMMC0>,
			 <&cru SCLK_SDMMC0_DRV>, <&cru SCLK_SDMMC0_SAMPLE>;
		clock-names = "biu", "ciu", "ciu-drive", "ciu-sample";
		fifo-depth = <0x100>;
		resets = <&cru SRST_SDMMC0>;
		reset-names = "reset";
		status = "disabled";
	};

	sdmmc1: dwmmc@fe2c0000 {
		compatible = "rockchip,rk3568-dw-mshc",
			     "rockchip,rk3288-dw-mshc";
		reg = <0x0 0xfe2c0000 0x0 0x4000>;
		interrupts = <GIC_SPI 99 IRQ_TYPE_LEVEL_HIGH>;
		max-frequency = <150000000>;
		clocks = <&cru HCLK_SDMMC1>, <&cru CLK_SDMMC1>,
			 <&cru SCLK_SDMMC1_DRV>, <&cru SCLK_SDMMC1_SAMPLE>;
		clock-names = "biu", "ciu", "ciu-drive", "ciu-sample";
		fifo-depth = <0x100>;
		resets = <&cru SRST_SDMMC1>;
		reset-names = "reset";
		status = "disabled";
	};

	sfc: spi@fe300000 {
		compatible = "rockchip,sfc";
		reg = <0x0 0xfe300000 0x0 0x4000>;
		interrupts = <GIC_SPI 101 IRQ_TYPE_LEVEL_HIGH>;
		clocks = <&cru SCLK_SFC>, <&cru HCLK_SFC>;
		clock-names = "clk_sfc", "hclk_sfc";
		assigned-clocks = <&cru SCLK_SFC>;
		assigned-clock-rates = <100000000>;
		#address-cells = <1>;
		#size-cells = <0>;
		status = "disabled";
	};

	sdhci: sdhci@fe310000 {
		compatible = "rockchip,rk3568-dwcmshc", "rockchip,dwcmshc-sdhci";
		reg = <0x0 0xfe310000 0x0 0x10000>;
		interrupts = <GIC_SPI 19 IRQ_TYPE_LEVEL_HIGH>;
		assigned-clocks = <&cru BCLK_EMMC>, <&cru TCLK_EMMC>,
				  <&cru CCLK_EMMC>;
		assigned-clock-rates = <200000000>, <24000000>, <200000000>;
		clocks = <&cru CCLK_EMMC>, <&cru HCLK_EMMC>,
			 <&cru ACLK_EMMC>, <&cru BCLK_EMMC>,
			 <&cru TCLK_EMMC>;
		clock-names = "core", "bus", "axi", "block", "timer";
		resets = <&cru SRST_C_EMMC>, <&cru SRST_H_EMMC>,
			 <&cru SRST_A_EMMC>, <&cru SRST_B_EMMC>,
			 <&cru SRST_T_EMMC>;
		reset-names = "core", "bus", "axi", "block", "timer";
		status = "disabled";
	};

	nandc0: nandc@fe330000 {
		compatible = "rockchip,rk-nandc-v9";
		reg = <0x0 0xfe330000 0x0 0x4000>;
		interrupts = <GIC_SPI 70 IRQ_TYPE_LEVEL_HIGH>;
		nandc_id = <0>;
		clocks = <&cru NCLK_NANDC>, <&cru HCLK_NANDC>;
		clock-names = "clk_nandc", "hclk_nandc";
		status = "disabled";
	};

	crypto: crypto@fe380000 {
		compatible = "rockchip,rk3568-crypto";
		reg = <0x0 0xfe380000 0x0 0x4000>;
		interrupts = <GIC_SPI 4 IRQ_TYPE_LEVEL_HIGH>;
		clocks = <&cru ACLK_CRYPTO_NS>, <&cru HCLK_CRYPTO_NS>,
			<&cru CLK_CRYPTO_NS_CORE>, <&cru CLK_CRYPTO_NS_PKA>;
		clock-names = "aclk", "hclk", "sclk", "apb_pclk";
		assigned-clocks = <&cru CLK_CRYPTO_NS_CORE>;
		assigned-clock-rates = <200000000>;
		resets = <&cru SRST_CRYPTO_NS_CORE>;
		reset-names = "crypto-rst";
		status = "disabled";
	};

	rng: rng@fe388000 {
		compatible = "rockchip,cryptov2-rng";
		reg = <0x0 0xfe388000 0x0 0x2000>;
		clocks = <&cru CLK_TRNG_NS>, <&cru HCLK_TRNG_NS>;
		clock-names = "clk_trng", "hclk_trng";
		resets = <&cru SRST_TRNG_NS>;
		reset-names = "reset";
		status = "disabled";
	};

	otp: otp@fe38c000 {
		compatible = "rockchip,rk3568-otp";
		reg = <0x0 0xfe38c000 0x0 0x4000>;
		#address-cells = <1>;
		#size-cells = <1>;
		clocks = <&cru CLK_OTPC_NS_USR>, <&cru CLK_OTPC_NS_SBPI>,
			 <&cru PCLK_OTPC_NS>, <&cru PCLK_OTPPHY>;
		clock-names = "usr", "sbpi", "apb", "phy";
		resets = <&cru SRST_OTPPHY>;
		reset-names = "otp_phy";

		/* Data cells */
		cpu_code: cpu-code@2 {
			reg = <0x02 0x2>;
		};
		otp_cpu_version: cpu-version@8 {
			reg = <0x08 0x1>;
			bits = <3 3>;
		};
		mbist_vmin: mbist-vmin@9 {
			reg = <0x09 0x1>;
			bits = <0 4>;
		};
		otp_id: id@a {
			reg = <0x0a 0x10>;
		};
		cpu_leakage: cpu-leakage@1a {
			reg = <0x1a 0x1>;
		};
		log_leakage: log-leakage@1b {
			reg = <0x1b 0x1>;
		};
		core_pvtm:core-pvtm@2a {
			reg = <0x2a 0x2>;
		};
		performance:performance@22 {
			reg = <0x22 0x1>;
			bits = <0 4>;
		};
		cpu_tsadc_trim_l: cpu-tsadc-trim-l@2e {
			reg = <0x2e 0x1>;
		};
		cpu_tsadc_trim_h: cpu-tsadc-trim-h@2f {
			reg = <0x2f 0x1>;
			bits = <0 4>;
		};
		tsadc_trim_base_frac: tsadc-trim-base-frac@31 {
			reg = <0x31 0x1>;
			bits = <4 4>;
		};
		tsadc_trim_base: tsadc-trim-base@32 {
			reg = <0x32 0x1>;
		};
		cpu_opp_info: cpu-opp-info@36 {
			reg = <0x36 0x6>;
		};
	};

	can0: can@fe570000 {
		compatible = "rockchip,rk3568-can-2.0";
		reg = <0x0 0xfe570000 0x0 0x1000>;
		interrupts = <GIC_SPI 1 IRQ_TYPE_LEVEL_HIGH>;
		clocks = <&cru CLK_CAN0>, <&cru PCLK_CAN0>;
		clock-names = "baudclk", "apb_pclk";
		resets = <&cru SRST_CAN0>, <&cru SRST_P_CAN0>;
		reset-names = "can", "can-apb";
		tx-fifo-depth = <1>;
		rx-fifo-depth = <6>;
		status = "disabled";
	};

	can1: can@fe580000 {
		compatible = "rockchip,rk3568-can-2.0";
		reg = <0x0 0xfe580000 0x0 0x1000>;
		interrupts = <GIC_SPI 2 IRQ_TYPE_LEVEL_HIGH>;
		clocks = <&cru CLK_CAN1>, <&cru PCLK_CAN1>;
		clock-names = "baudclk", "apb_pclk";
		resets = <&cru SRST_CAN1>, <&cru SRST_P_CAN1>;
		reset-names = "can", "can-apb";
		tx-fifo-depth = <1>;
		rx-fifo-depth = <6>;
		status = "disabled";
	};

	can2: can@fe590000 {
		compatible = "rockchip,rk3568-can-2.0";
		reg = <0x0 0xfe590000 0x0 0x1000>;
		interrupts = <GIC_SPI 3 IRQ_TYPE_LEVEL_HIGH>;
		clocks = <&cru CLK_CAN2>, <&cru PCLK_CAN2>;
		clock-names = "baudclk", "apb_pclk";
		resets = <&cru SRST_CAN2>, <&cru SRST_P_CAN2>;
		reset-names = "can", "can-apb";
		tx-fifo-depth = <1>;
		rx-fifo-depth = <6>;
		status = "disabled";
	};


	rktimer: timer@fe5f0000 {
		compatible = "rockchip,rk3568-timer", "rockchip,rk3288-timer";
		reg = <0x0 0xfe5f0000 0x0 0x1000>;
		interrupts = <GIC_SPI 109 IRQ_TYPE_LEVEL_HIGH>;
		clocks = <&cru PCLK_TIMER>, <&cru CLK_TIMER0>;
		clock-names = "pclk", "timer";
	};

	wdt: watchdog@fe600000 {
		compatible = "snps,dw-wdt";
		reg = <0x0 0xfe600000 0x0 0x100>;
		clocks = <&cru TCLK_WDT_NS>, <&cru PCLK_WDT_NS>;
		clock-names = "tclk", "pclk";
		interrupts = <GIC_SPI 149 IRQ_TYPE_LEVEL_HIGH>;
		status = "okay";
	};

	mailbox: mailbox@fe780000 {
		compatible = "rockchip,rk3568-mailbox",
			     "rockchip,rk3368-mailbox";
		reg = <0x0 0xfe780000 0x0 0x1000>;
		interrupts = <GIC_SPI 183 IRQ_TYPE_LEVEL_HIGH>,
			     <GIC_SPI 184 IRQ_TYPE_LEVEL_HIGH>,
			     <GIC_SPI 185 IRQ_TYPE_LEVEL_HIGH>,
			     <GIC_SPI 186 IRQ_TYPE_LEVEL_HIGH>;
		clocks = <&cru PCLK_MAILBOX>;
		clock-names = "pclk_mailbox";
		#mbox-cells = <1>;
		status = "disabled";
	};

	combphy0_us: phy@fe820000 {
		compatible = "rockchip,rk3568-naneng-combphy";
		reg = <0x0 0xfe820000 0x0 0x100>;
		#phy-cells = <1>;
		clocks = <&pmucru CLK_PCIEPHY0_REF>, <&cru PCLK_PIPEPHY0>,
			 <&cru PCLK_PIPE>;
		clock-names = "refclk", "apbclk", "pipe_clk";
		assigned-clocks = <&pmucru CLK_PCIEPHY0_REF>;
		assigned-clock-rates = <100000000>;
		resets = <&cru SRST_P_PIPEPHY0>, <&cru SRST_PIPEPHY0>;
		reset-names = "combphy-apb", "combphy";
		rockchip,pipe-grf = <&pipegrf>;
		rockchip,pipe-phy-grf = <&pipe_phy_grf0>;
		status = "disabled";
	};

	combphy1_usq: phy@fe830000 {
		compatible = "rockchip,rk3568-naneng-combphy";
		reg = <0x0 0xfe830000 0x0 0x100>;
		#phy-cells = <1>;
		clocks = <&pmucru CLK_PCIEPHY1_REF>, <&cru PCLK_PIPEPHY1>,
			 <&cru PCLK_PIPE>;
		clock-names = "refclk", "apbclk", "pipe_clk";
		assigned-clocks = <&pmucru CLK_PCIEPHY1_REF>;
		assigned-clock-rates = <100000000>;
		resets = <&cru SRST_P_PIPEPHY1>, <&cru SRST_PIPEPHY1>;
		reset-names = "combphy-apb", "combphy";
		rockchip,pipe-grf = <&pipegrf>;
		rockchip,pipe-phy-grf = <&pipe_phy_grf1>;
		status = "disabled";
	};

	combphy2_psq: phy@fe840000 {
		compatible = "rockchip,rk3568-naneng-combphy";
		reg = <0x0 0xfe840000 0x0 0x100>;
		#phy-cells = <1>;
		clocks = <&pmucru CLK_PCIEPHY2_REF>, <&cru PCLK_PIPEPHY2>,
			 <&cru PCLK_PIPE>;
		clock-names = "refclk", "apbclk", "pipe_clk";
		assigned-clocks = <&pmucru CLK_PCIEPHY2_REF>;
		assigned-clock-rates = <100000000>;
		resets = <&cru SRST_P_PIPEPHY2>, <&cru SRST_PIPEPHY2>;
		reset-names = "combphy-apb", "combphy";
		rockchip,pipe-grf = <&pipegrf>;
		rockchip,pipe-phy-grf = <&pipe_phy_grf2>;
		status = "disabled";
	};

    pinctrl: pinctrl {
        compatible = "rockchip,rk3568-pinctrl";
        rockchip,grf = <&grf>;
        rockchip,pmu = <&pmugrf>;
        #address-cells = <2>;
        #size-cells = <2>;
        ranges;

        /omit-if-no-ref/
        pcfg_pull_up: pcfg-pull-up {
            bias-pull-up;
        };

        /omit-if-no-ref/
        pcfg_pull_down: pcfg-pull-down {
            bias-pull-down;
        };

        /omit-if-no-ref/
        pcfg_pull_none: pcfg-pull-none {
            bias-disable;
        };

        /omit-if-no-ref/
        pcfg_pull_none_drv_level_0: pcfg-pull-none-drv-level-0 {
            bias-disable;
            drive-strength = <0>;
        };

        /omit-if-no-ref/
        pcfg_pull_none_drv_level_1: pcfg-pull-none-drv-level-1 {
            bias-disable;
            drive-strength = <1>;
        };

        /omit-if-no-ref/
        pcfg_pull_none_drv_level_2: pcfg-pull-none-drv-level-2 {
            bias-disable;
            drive-strength = <2>;
        };

        /omit-if-no-ref/
        pcfg_pull_none_drv_level_3: pcfg-pull-none-drv-level-3 {
            bias-disable;
            drive-strength = <3>;
        };

        /omit-if-no-ref/
        pcfg_pull_none_drv_level_4: pcfg-pull-none-drv-level-4 {
            bias-disable;
            drive-strength = <4>;
        };

        /omit-if-no-ref/
        pcfg_pull_none_drv_level_5: pcfg-pull-none-drv-level-5 {
            bias-disable;
            drive-strength = <5>;
        };

        /omit-if-no-ref/
        pcfg_pull_none_drv_level_6: pcfg-pull-none-drv-level-6 {
            bias-disable;
            drive-strength = <6>;
        };

        /omit-if-no-ref/
        pcfg_pull_none_drv_level_7: pcfg-pull-none-drv-level-7 {
            bias-disable;
            drive-strength = <7>;
        };

        /omit-if-no-ref/
        pcfg_pull_none_drv_level_8: pcfg-pull-none-drv-level-8 {
            bias-disable;
            drive-strength = <8>;
        };

        /omit-if-no-ref/
        pcfg_pull_none_drv_level_9: pcfg-pull-none-drv-level-9 {
            bias-disable;
            drive-strength = <9>;
        };

        /omit-if-no-ref/
        pcfg_pull_none_drv_level_10: pcfg-pull-none-drv-level-10 {
            bias-disable;
            drive-strength = <10>;
        };

        /omit-if-no-ref/
        pcfg_pull_none_drv_level_11: pcfg-pull-none-drv-level-11 {
            bias-disable;
            drive-strength = <11>;
        };

        /omit-if-no-ref/
        pcfg_pull_none_drv_level_12: pcfg-pull-none-drv-level-12 {
            bias-disable;
            drive-strength = <12>;
        };

        /omit-if-no-ref/
        pcfg_pull_none_drv_level_13: pcfg-pull-none-drv-level-13 {
            bias-disable;
            drive-strength = <13>;
        };

        /omit-if-no-ref/
        pcfg_pull_none_drv_level_14: pcfg-pull-none-drv-level-14 {
            bias-disable;
            drive-strength = <14>;
        };

        /omit-if-no-ref/
        pcfg_pull_none_drv_level_15: pcfg-pull-none-drv-level-15 {
            bias-disable;
            drive-strength = <15>;
        };

        /omit-if-no-ref/
        pcfg_pull_up_drv_level_0: pcfg-pull-up-drv-level-0 {
            bias-pull-up;
            drive-strength = <0>;
        };

        /omit-if-no-ref/
        pcfg_pull_up_drv_level_1: pcfg-pull-up-drv-level-1 {
            bias-pull-up;
            drive-strength = <1>;
        };

        /omit-if-no-ref/
        pcfg_pull_up_drv_level_2: pcfg-pull-up-drv-level-2 {
            bias-pull-up;
            drive-strength = <2>;
        };

        /omit-if-no-ref/
        pcfg_pull_up_drv_level_3: pcfg-pull-up-drv-level-3 {
            bias-pull-up;
            drive-strength = <3>;
        };

        /omit-if-no-ref/
        pcfg_pull_up_drv_level_4: pcfg-pull-up-drv-level-4 {
            bias-pull-up;
            drive-strength = <4>;
        };

        /omit-if-no-ref/
        pcfg_pull_up_drv_level_5: pcfg-pull-up-drv-level-5 {
            bias-pull-up;
            drive-strength = <5>;
        };

        /omit-if-no-ref/
        pcfg_pull_up_drv_level_6: pcfg-pull-up-drv-level-6 {
            bias-pull-up;
            drive-strength = <6>;
        };

        /omit-if-no-ref/
        pcfg_pull_up_drv_level_7: pcfg-pull-up-drv-level-7 {
            bias-pull-up;
            drive-strength = <7>;
        };

        /omit-if-no-ref/
        pcfg_pull_up_drv_level_8: pcfg-pull-up-drv-level-8 {
            bias-pull-up;
            drive-strength = <8>;
        };

        /omit-if-no-ref/
        pcfg_pull_up_drv_level_9: pcfg-pull-up-drv-level-9 {
            bias-pull-up;
            drive-strength = <9>;
        };

        /omit-if-no-ref/
        pcfg_pull_up_drv_level_10: pcfg-pull-up-drv-level-10 {
            bias-pull-up;
            drive-strength = <10>;
        };

        /omit-if-no-ref/
        pcfg_pull_up_drv_level_11: pcfg-pull-up-drv-level-11 {
            bias-pull-up;
            drive-strength = <11>;
        };

        /omit-if-no-ref/
        pcfg_pull_up_drv_level_12: pcfg-pull-up-drv-level-12 {
            bias-pull-up;
            drive-strength = <12>;
        };

        /omit-if-no-ref/
        pcfg_pull_up_drv_level_13: pcfg-pull-up-drv-level-13 {
            bias-pull-up;
            drive-strength = <13>;
        };

        /omit-if-no-ref/
        pcfg_pull_up_drv_level_14: pcfg-pull-up-drv-level-14 {
            bias-pull-up;
            drive-strength = <14>;
        };

        /omit-if-no-ref/
        pcfg_pull_up_drv_level_15: pcfg-pull-up-drv-level-15 {
            bias-pull-up;
            drive-strength = <15>;
        };

        /omit-if-no-ref/
        pcfg_pull_down_drv_level_0: pcfg-pull-down-drv-level-0 {
            bias-pull-down;
            drive-strength = <0>;
        };

        /omit-if-no-ref/
        pcfg_pull_down_drv_level_1: pcfg-pull-down-drv-level-1 {
            bias-pull-down;
            drive-strength = <1>;
        };

        /omit-if-no-ref/
        pcfg_pull_down_drv_level_2: pcfg-pull-down-drv-level-2 {
            bias-pull-down;
            drive-strength = <2>;
        };

        /omit-if-no-ref/
        pcfg_pull_down_drv_level_3: pcfg-pull-down-drv-level-3 {
            bias-pull-down;
            drive-strength = <3>;
        };

        /omit-if-no-ref/
        pcfg_pull_down_drv_level_4: pcfg-pull-down-drv-level-4 {
            bias-pull-down;
            drive-strength = <4>;
        };

        /omit-if-no-ref/
        pcfg_pull_down_drv_level_5: pcfg-pull-down-drv-level-5 {
            bias-pull-down;
            drive-strength = <5>;
        };

        /omit-if-no-ref/
        pcfg_pull_down_drv_level_6: pcfg-pull-down-drv-level-6 {
            bias-pull-down;
            drive-strength = <6>;
        };

        /omit-if-no-ref/
        pcfg_pull_down_drv_level_7: pcfg-pull-down-drv-level-7 {
            bias-pull-down;
            drive-strength = <7>;
        };

        /omit-if-no-ref/
        pcfg_pull_down_drv_level_8: pcfg-pull-down-drv-level-8 {
            bias-pull-down;
            drive-strength = <8>;
        };

        /omit-if-no-ref/
        pcfg_pull_down_drv_level_9: pcfg-pull-down-drv-level-9 {
            bias-pull-down;
            drive-strength = <9>;
        };

        /omit-if-no-ref/
        pcfg_pull_down_drv_level_10: pcfg-pull-down-drv-level-10 {
            bias-pull-down;
            drive-strength = <10>;
        };

        /omit-if-no-ref/
        pcfg_pull_down_drv_level_11: pcfg-pull-down-drv-level-11 {
            bias-pull-down;
            drive-strength = <11>;
        };

        /omit-if-no-ref/
        pcfg_pull_down_drv_level_12: pcfg-pull-down-drv-level-12 {
            bias-pull-down;
            drive-strength = <12>;
        };

        /omit-if-no-ref/
        pcfg_pull_down_drv_level_13: pcfg-pull-down-drv-level-13 {
            bias-pull-down;
            drive-strength = <13>;
        };

        /omit-if-no-ref/
        pcfg_pull_down_drv_level_14: pcfg-pull-down-drv-level-14 {
            bias-pull-down;
            drive-strength = <14>;
        };

        /omit-if-no-ref/
        pcfg_pull_down_drv_level_15: pcfg-pull-down-drv-level-15 {
            bias-pull-down;
            drive-strength = <15>;
        };

        /omit-if-no-ref/
        pcfg_pull_up_smt: pcfg-pull-up-smt {
            bias-pull-up;
            input-schmitt-enable;
        };

        /omit-if-no-ref/
        pcfg_pull_down_smt: pcfg-pull-down-smt {
            bias-pull-down;
            input-schmitt-enable;
        };

        /omit-if-no-ref/
        pcfg_pull_none_smt: pcfg-pull-none-smt {
            bias-disable;
            input-schmitt-enable;
        };

        /omit-if-no-ref/
        pcfg_pull_none_drv_level_0_smt: pcfg-pull-none-drv-level-0-smt {
            bias-disable;
            drive-strength = <0>;
            input-schmitt-enable;
        };

        /omit-if-no-ref/
        pcfg_pull_none_drv_level_1_smt: pcfg-pull-none-drv-level-1-smt {
            bias-disable;
            drive-strength = <1>;
            input-schmitt-enable;
        };

        /omit-if-no-ref/
        pcfg_pull_none_drv_level_2_smt: pcfg-pull-none-drv-level-2-smt {
            bias-disable;
            drive-strength = <2>;
            input-schmitt-enable;
        };

        /omit-if-no-ref/
        pcfg_pull_none_drv_level_3_smt: pcfg-pull-none-drv-level-3-smt {
            bias-disable;
            drive-strength = <3>;
            input-schmitt-enable;
        };

        /omit-if-no-ref/
        pcfg_pull_none_drv_level_4_smt: pcfg-pull-none-drv-level-4-smt {
            bias-disable;
            drive-strength = <4>;
            input-schmitt-enable;
        };

        /omit-if-no-ref/
        pcfg_pull_none_drv_level_5_smt: pcfg-pull-none-drv-level-5-smt {
            bias-disable;
            drive-strength = <5>;
            input-schmitt-enable;
        };

        /omit-if-no-ref/
        pcfg_output_high: pcfg-output-high {
            output-high;
        };

        /omit-if-no-ref/
        pcfg_output_high_pull_up: pcfg-output-high-pull-up {
            output-high;
            bias-pull-up;
        };

        /omit-if-no-ref/
        pcfg_output_high_pull_down: pcfg-output-high-pull-down {
            output-high;
            bias-pull-down;
        };

        /omit-if-no-ref/
        pcfg_output_high_pull_none: pcfg-output-high-pull-none {
            output-high;
            bias-disable;
        };

        /omit-if-no-ref/
        pcfg_output_low: pcfg-output-low {
            output-low;
        };

        /omit-if-no-ref/
        pcfg_output_low_pull_up: pcfg-output-low-pull-up {
            output-low;
            bias-pull-up;
        };

        /omit-if-no-ref/
        pcfg_output_low_pull_down: pcfg-output-low-pull-down {
            output-low;
            bias-pull-down;
        };

        /omit-if-no-ref/
        pcfg_output_low_pull_none: pcfg-output-low-pull-none {
            output-low;
            bias-disable;
        };

        gpio0: gpio0@fdd60000 {
            compatible = "rockchip,gpio-bank";
            reg = <0x0 0xfdd60000 0x0 0x100>;
            interrupts = <GIC_SPI 33 IRQ_TYPE_LEVEL_HIGH>;
            clocks = <&pmucru PCLK_GPIO0>, <&pmucru DBCLK_GPIO0>;

            gpio-controller;
            #gpio-cells = <2>;
            interrupt-controller;
            #interrupt-cells = <2>;
        };

        gpio1: gpio1@fe740000 {
            compatible = "rockchip,gpio-bank";
            reg = <0x0 0xfe740000 0x0 0x100>;
            interrupts = <GIC_SPI 34 IRQ_TYPE_LEVEL_HIGH>;
            clocks = <&cru PCLK_GPIO1>, <&cru DBCLK_GPIO1>;

            gpio-controller;
            #gpio-cells = <2>;
            interrupt-controller;
            #interrupt-cells = <2>;
        };

        gpio2: gpio2@fe750000 {
            compatible = "rockchip,gpio-bank";
            reg = <0x0 0xfe750000 0x0 0x100>;
            interrupts = <GIC_SPI 35 IRQ_TYPE_LEVEL_HIGH>;
            clocks = <&cru PCLK_GPIO2>, <&cru DBCLK_GPIO2>;

            gpio-controller;
            #gpio-cells = <2>;
            interrupt-controller;
            #interrupt-cells = <2>;
        };

        gpio3: gpio3@fe760000 {
            compatible = "rockchip,gpio-bank";
            reg = <0x0 0xfe760000 0x0 0x100>;
            interrupts = <GIC_SPI 36 IRQ_TYPE_LEVEL_HIGH>;
            clocks = <&cru PCLK_GPIO3>, <&cru DBCLK_GPIO3>;

            gpio-controller;
            #gpio-cells = <2>;
            interrupt-controller;
            #interrupt-cells = <2>;
        };

        gpio4: gpio4@fe770000 {
            compatible = "rockchip,gpio-bank";
            reg = <0x0 0xfe770000 0x0 0x100>;
            interrupts = <GIC_SPI 37 IRQ_TYPE_LEVEL_HIGH>;
            clocks = <&cru PCLK_GPIO4>, <&cru DBCLK_GPIO4>;

            gpio-controller;
            #gpio-cells = <2>;
            interrupt-controller;
            #interrupt-cells = <2>;
        };

        cam {
            /omit-if-no-ref/
            cam_clkout0: cam-clkout0 {
                rockchip,pins =
                    /* cam_clkout0 */
                    <4 RK_PA7 1 &pcfg_pull_none>;
            };

            /omit-if-no-ref/
            cam_clkout1: cam-clkout1 {
                rockchip,pins =
                    /* cam_clkout1 */
                    <4 RK_PB0 1 &pcfg_pull_none>;
            };
        };

        can0 {
            /omit-if-no-ref/
            can0m0_pins: can0m0-pins {
                rockchip,pins =
                    /* can0_rxm0 */
                    <0 RK_PB4 2 &pcfg_pull_none>,
                    /* can0_txm0 */
                    <0 RK_PB3 2 &pcfg_pull_none>;
            };

            /omit-if-no-ref/
            can0m1_pins: can0m1-pins {
                rockchip,pins =
                    /* can0_rxm1 */
                    <2 RK_PA2 4 &pcfg_pull_none>,
                    /* can0_txm1 */
                    <2 RK_PA1 4 &pcfg_pull_none>;
            };
        };

        can1 {
            /omit-if-no-ref/
            can1m0_pins: can1m0-pins {
                rockchip,pins =
                    /* can1_rxm0 */
                    <1 RK_PA0 3 &pcfg_pull_none>,
                    /* can1_txm0 */
                    <1 RK_PA1 3 &pcfg_pull_none>;
            };

            /omit-if-no-ref/
            can1m1_pins: can1m1-pins {
                rockchip,pins =
                    /* can1_rxm1 */
                    <4 RK_PC2 3 &pcfg_pull_none>,
                    /* can1_txm1 */
                    <4 RK_PC3 3 &pcfg_pull_none>;
            };
        };

        can2 {
            /omit-if-no-ref/
            can2m0_pins: can2m0-pins {
                rockchip,pins =
                    /* can2_rxm0 */
                    <4 RK_PB4 3 &pcfg_pull_none>,
                    /* can2_txm0 */
                    <4 RK_PB5 3 &pcfg_pull_none>;
            };

            /omit-if-no-ref/
            can2m1_pins: can2m1-pins {
                rockchip,pins =
                    /* can2_rxm1 */
                    <2 RK_PB1 4 &pcfg_pull_none>,
                    /* can2_txm1 */
                    <2 RK_PB2 4 &pcfg_pull_none>;
            };
        };

        clk32k {
            /omit-if-no-ref/
            clk32k_in: clk32k-in {
                rockchip,pins =
                    /* clk32k_in */
                    <0 RK_PB0 1 &pcfg_pull_none>;
            };

            /omit-if-no-ref/
            clk32k_out0: clk32k-out0 {
                rockchip,pins =
                    /* clk32k_out0 */
                    <0 RK_PB0 2 &pcfg_pull_none>;
            };

            /omit-if-no-ref/
            clk32k_out1: clk32k-out1 {
                rockchip,pins =
                    /* clk32k_out1 */
                    <2 RK_PC6 1 &pcfg_pull_none>;
            };
        };

        cpu {
            /omit-if-no-ref/
            cpu_pins: cpu-pins {
                rockchip,pins =
                    /* cpu_avs */
                    <0 RK_PB7 2 &pcfg_pull_none>;
            };
        };

        ebc {
            /omit-if-no-ref/
            ebc_extern: ebc-extern {
                rockchip,pins =
                    /* ebc_sdce1 */
                    <4 RK_PA7 2 &pcfg_pull_none>,
                    /* ebc_sdce2 */
                    <4 RK_PB0 2 &pcfg_pull_none>,
                    /* ebc_sdce3 */
                    <4 RK_PB1 2 &pcfg_pull_none>,
                    /* ebc_sdshr */
                    <4 RK_PB5 2 &pcfg_pull_none>,
                    /* ebc_vcom */
                    <4 RK_PB2 2 &pcfg_pull_none>;
            };

            /omit-if-no-ref/
            ebc_pins: ebc-pins {
                rockchip,pins =
                    /* ebc_gdclk */
                    <4 RK_PC0 2 &pcfg_pull_none>,
                    /* ebc_gdoe */
                    <4 RK_PB3 2 &pcfg_pull_none>,
                    /* ebc_gdsp */
                    <4 RK_PB4 2 &pcfg_pull_none>,
                    /* ebc_sdce0 */
                    <4 RK_PA6 2 &pcfg_pull_none>,
                    /* ebc_sdclk */
                    <4 RK_PC1 2 &pcfg_pull_none>,
                    /* ebc_sddo0 */
                    <3 RK_PC6 2 &pcfg_pull_none>,
                    /* ebc_sddo1 */
                    <3 RK_PC7 2 &pcfg_pull_none>,
                    /* ebc_sddo2 */
                    <3 RK_PD0 2 &pcfg_pull_none>,
                    /* ebc_sddo3 */
                    <3 RK_PD1 2 &pcfg_pull_none>,
                    /* ebc_sddo4 */
                    <3 RK_PD2 2 &pcfg_pull_none>,
                    /* ebc_sddo5 */
                    <3 RK_PD3 2 &pcfg_pull_none>,
                    /* ebc_sddo6 */
                    <3 RK_PD4 2 &pcfg_pull_none>,
                    /* ebc_sddo7 */
                    <3 RK_PD5 2 &pcfg_pull_none>,
                    /* ebc_sddo8 */
                    <3 RK_PD6 2 &pcfg_pull_none>,
                    /* ebc_sddo9 */
                    <3 RK_PD7 2 &pcfg_pull_none>,
                    /* ebc_sddo10 */
                    <4 RK_PA0 2 &pcfg_pull_none>,
                    /* ebc_sddo11 */
                    <4 RK_PA1 2 &pcfg_pull_none>,
                    /* ebc_sddo12 */
                    <4 RK_PA2 2 &pcfg_pull_none>,
                    /* ebc_sddo13 */
                    <4 RK_PA3 2 &pcfg_pull_none>,
                    /* ebc_sddo14 */
                    <4 RK_PA4 2 &pcfg_pull_none>,
                    /* ebc_sddo15 */
                    <4 RK_PA5 2 &pcfg_pull_none>,
                    /* ebc_sdle */
                    <4 RK_PB6 2 &pcfg_pull_none>,
                    /* ebc_sdoe */
                    <4 RK_PB7 2 &pcfg_pull_none>;
            };
        };

        edpdp {
            /omit-if-no-ref/
            edpdpm0_pins: edpdpm0-pins {
                rockchip,pins =
                    /* edpdp_hpdinm0 */
                    <4 RK_PC4 1 &pcfg_pull_none>;
            };

            /omit-if-no-ref/
            edpdpm1_pins: edpdpm1-pins {
                rockchip,pins =
                    /* edpdp_hpdinm1 */
                    <0 RK_PC2 2 &pcfg_pull_none>;
            };
        };

        emmc {
            /omit-if-no-ref/
            emmc_rstnout: emmc-rstnout {
                rockchip,pins =
                    /* emmc_rstn */
                    <1 RK_PC7 1 &pcfg_pull_none>;
            };

            /omit-if-no-ref/
            emmc_bus8: emmc-bus8 {
                rockchip,pins =
                    /* emmc_d0 */
                    <1 RK_PB4 1 &pcfg_pull_up_drv_level_2>,
                    /* emmc_d1 */
                    <1 RK_PB5 1 &pcfg_pull_up_drv_level_2>,
                    /* emmc_d2 */
                    <1 RK_PB6 1 &pcfg_pull_up_drv_level_2>,
                    /* emmc_d3 */
                    <1 RK_PB7 1 &pcfg_pull_up_drv_level_2>,
                    /* emmc_d4 */
                    <1 RK_PC0 1 &pcfg_pull_up_drv_level_2>,
                    /* emmc_d5 */
                    <1 RK_PC1 1 &pcfg_pull_up_drv_level_2>,
                    /* emmc_d6 */
                    <1 RK_PC2 1 &pcfg_pull_up_drv_level_2>,
                    /* emmc_d7 */
                    <1 RK_PC3 1 &pcfg_pull_up_drv_level_2>;
            };

            /omit-if-no-ref/
            emmc_clk: emmc-clk {
                rockchip,pins =
                    /* emmc_clkout */
                    <1 RK_PC5 1 &pcfg_pull_up_drv_level_2>;
            };

            /omit-if-no-ref/
            emmc_cmd: emmc-cmd {
                rockchip,pins =
                    /* emmc_cmd */
                    <1 RK_PC4 1 &pcfg_pull_up_drv_level_2>;
            };

            /omit-if-no-ref/
            emmc_datastrobe: emmc-datastrobe {
                rockchip,pins =
                    /* emmc_datastrobe */
                    <1 RK_PC6 1 &pcfg_pull_none>;
            };
        };

        flash {
            /omit-if-no-ref/
            flash_pins: flash-pins {
                rockchip,pins =
                    /* flash_ale */
                    <1 RK_PD0 2 &pcfg_pull_none>,
                    /* flash_cle */
                    <1 RK_PC6 3 &pcfg_pull_none>,
                    /* flash_cs0n */
                    <1 RK_PD3 2 &pcfg_pull_none>,
                    /* flash_cs1n */
                    <1 RK_PD4 2 &pcfg_pull_none>,
                    /* flash_d0 */
                    <1 RK_PB4 2 &pcfg_pull_none>,
                    /* flash_d1 */
                    <1 RK_PB5 2 &pcfg_pull_none>,
                    /* flash_d2 */
                    <1 RK_PB6 2 &pcfg_pull_none>,
                    /* flash_d3 */
                    <1 RK_PB7 2 &pcfg_pull_none>,
                    /* flash_d4 */
                    <1 RK_PC0 2 &pcfg_pull_none>,
                    /* flash_d5 */
                    <1 RK_PC1 2 &pcfg_pull_none>,
                    /* flash_d6 */
                    <1 RK_PC2 2 &pcfg_pull_none>,
                    /* flash_d7 */
                    <1 RK_PC3 2 &pcfg_pull_none>,
                    /* flash_dqs */
                    <1 RK_PC5 2 &pcfg_pull_none>,
                    /* flash_rdn */
                    <1 RK_PD2 2 &pcfg_pull_none>,
                    /* flash_rdy */
                    <1 RK_PD1 2 &pcfg_pull_none>,
                    /* flash_volsel */
                    <0 RK_PA7 1 &pcfg_pull_none>,
                    /* flash_wpn */
                    <1 RK_PC7 3 &pcfg_pull_none>,
                    /* flash_wrn */
                    <1 RK_PC4 2 &pcfg_pull_none>;
            };
        };

        fspi {
            /omit-if-no-ref/
            fspi_pins: fspi-pins {
                rockchip,pins =
                    /* fspi_clk */
                    <1 RK_PD0 1 &pcfg_pull_none>,
                    /* fspi_cs0n */
                    <1 RK_PD3 1 &pcfg_pull_none>,
                    /* fspi_d0 */
                    <1 RK_PD1 1 &pcfg_pull_none>,
                    /* fspi_d1 */
                    <1 RK_PD2 1 &pcfg_pull_none>,
                    /* fspi_d2 */
                    <1 RK_PC7 2 &pcfg_pull_none>,
                    /* fspi_d3 */
                    <1 RK_PD4 1 &pcfg_pull_none>;
            };

            /omit-if-no-ref/
            fspi_cs1: fspi-cs1 {
                rockchip,pins =
                    /* fspi_cs1n */
                    <1 RK_PC6 2 &pcfg_pull_up>;
            };
        };

        i2c0 {
            /omit-if-no-ref/
            i2c0_xfer: i2c0-xfer {
                rockchip,pins =
                    /* i2c0_scl */
                    <0 RK_PB1 1 &pcfg_pull_none_smt>,
                    /* i2c0_sda */
                    <0 RK_PB2 1 &pcfg_pull_none_smt>;
            };
        };

        i2c1 {
            /omit-if-no-ref/
            i2c1_xfer: i2c1-xfer {
                rockchip,pins =
                    /* i2c1_scl */
                    <0 RK_PB3 1 &pcfg_pull_none_smt>,
                    /* i2c1_sda */
                    <0 RK_PB4 1 &pcfg_pull_none_smt>;
            };
        };

        i2c2 {
            /omit-if-no-ref/
            i2c2m0_xfer: i2c2m0-xfer {
                rockchip,pins =
                    /* i2c2_sclm0 */
                    <0 RK_PB5 1 &pcfg_pull_none_smt>,
                    /* i2c2_sdam0 */
                    <0 RK_PB6 1 &pcfg_pull_none_smt>;
            };

            /omit-if-no-ref/
            i2c2m1_xfer: i2c2m1-xfer {
                rockchip,pins =
                    /* i2c2_sclm1 */
                    <4 RK_PB5 1 &pcfg_pull_none_smt>,
                    /* i2c2_sdam1 */
                    <4 RK_PB4 1 &pcfg_pull_none_smt>;
            };
        };

        i2c3 {
            /omit-if-no-ref/
            i2c3m0_xfer: i2c3m0-xfer {
                rockchip,pins =
                    /* i2c3_sclm0 */
                    <1 RK_PA1 1 &pcfg_pull_none_smt>,
                    /* i2c3_sdam0 */
                    <1 RK_PA0 1 &pcfg_pull_none_smt>;
            };

            /omit-if-no-ref/
            i2c3m1_xfer: i2c3m1-xfer {
                rockchip,pins =
                    /* i2c3_sclm1 */
                    <3 RK_PB5 4 &pcfg_pull_none_smt>,
                    /* i2c3_sdam1 */
                    <3 RK_PB6 4 &pcfg_pull_none_smt>;
            };
        };

        i2c4 {
            /omit-if-no-ref/
            i2c4m0_xfer: i2c4m0-xfer {
                rockchip,pins =
                    /* i2c4_sclm0 */
                    <4 RK_PB3 1 &pcfg_pull_none_smt>,
                    /* i2c4_sdam0 */
                    <4 RK_PB2 1 &pcfg_pull_none_smt>;
            };

            /omit-if-no-ref/
            i2c4m1_xfer: i2c4m1-xfer {
                rockchip,pins =
                    /* i2c4_sclm1 */
                    <2 RK_PB2 2 &pcfg_pull_none_smt>,
                    /* i2c4_sdam1 */
                    <2 RK_PB1 2 &pcfg_pull_none_smt>;
            };
        };

        i2c5 {
            /omit-if-no-ref/
            i2c5m0_xfer: i2c5m0-xfer {
                rockchip,pins =
                    /* i2c5_sclm0 */
                    <3 RK_PB3 4 &pcfg_pull_none_smt>,
                    /* i2c5_sdam0 */
                    <3 RK_PB4 4 &pcfg_pull_none_smt>;
            };

            /omit-if-no-ref/
            i2c5m1_xfer: i2c5m1-xfer {
                rockchip,pins =
                    /* i2c5_sclm1 */
                    <4 RK_PC7 2 &pcfg_pull_none_smt>,
                    /* i2c5_sdam1 */
                    <4 RK_PD0 2 &pcfg_pull_none_smt>;
            };
        };

        lcdc {
            /omit-if-no-ref/
            lcdc_ctl: lcdc-ctl {
                rockchip,pins =
                    /* lcdc_clk */
                    <3 RK_PA0 1 &pcfg_pull_none>,
                    /* lcdc_d0 */
                    <2 RK_PD0 1 &pcfg_pull_none>,
                    /* lcdc_d1 */
                    <2 RK_PD1 1 &pcfg_pull_none>,
                    /* lcdc_d2 */
                    <2 RK_PD2 1 &pcfg_pull_none>,
                    /* lcdc_d3 */
                    <2 RK_PD3 1 &pcfg_pull_none>,
                    /* lcdc_d4 */
                    <2 RK_PD4 1 &pcfg_pull_none>,
                    /* lcdc_d5 */
                    <2 RK_PD5 1 &pcfg_pull_none>,
                    /* lcdc_d6 */
                    <2 RK_PD6 1 &pcfg_pull_none>,
                    /* lcdc_d7 */
                    <2 RK_PD7 1 &pcfg_pull_none>,
                    /* lcdc_d8 */
                    <3 RK_PA1 1 &pcfg_pull_none>,
                    /* lcdc_d9 */
                    <3 RK_PA2 1 &pcfg_pull_none>,
                    /* lcdc_d10 */
                    <3 RK_PA3 1 &pcfg_pull_none>,
                    /* lcdc_d11 */
                    <3 RK_PA4 1 &pcfg_pull_none>,
                    /* lcdc_d12 */
                    <3 RK_PA5 1 &pcfg_pull_none>,
                    /* lcdc_d13 */
                    <3 RK_PA6 1 &pcfg_pull_none>,
                    /* lcdc_d14 */
                    <3 RK_PA7 1 &pcfg_pull_none>,
                    /* lcdc_d15 */
                    <3 RK_PB0 1 &pcfg_pull_none>,
                    /* lcdc_d16 */
                    <3 RK_PB1 1 &pcfg_pull_none>,
                    /* lcdc_d17 */
                    <3 RK_PB2 1 &pcfg_pull_none>,
                    /* lcdc_d18 */
                    <3 RK_PB3 1 &pcfg_pull_none>,
                    /* lcdc_d19 */
                    <3 RK_PB4 1 &pcfg_pull_none>,
                    /* lcdc_d20 */
                    <3 RK_PB5 1 &pcfg_pull_none>,
                    /* lcdc_d21 */
                    <3 RK_PB6 1 &pcfg_pull_none>,
                    /* lcdc_d22 */
                    <3 RK_PB7 1 &pcfg_pull_none>,
                    /* lcdc_d23 */
                    <3 RK_PC0 1 &pcfg_pull_none>,
                    /* lcdc_den */
                    <3 RK_PC3 1 &pcfg_pull_none>,
                    /* lcdc_hsync */
                    <3 RK_PC1 1 &pcfg_pull_none>,
                    /* lcdc_vsync */
                    <3 RK_PC2 1 &pcfg_pull_none>;
            };
        };

        mcu {
            /omit-if-no-ref/
            mcu_pins: mcu-pins {
                rockchip,pins =
                    /* mcu_jtagtck */
                    <0 RK_PB4 4 &pcfg_pull_none>,
                    /* mcu_jtagtdi */
                    <0 RK_PC1 4 &pcfg_pull_none>,
                    /* mcu_jtagtdo */
                    <0 RK_PB3 4 &pcfg_pull_none>,
                    /* mcu_jtagtms */
                    <0 RK_PC2 4 &pcfg_pull_none>,
                    /* mcu_jtagtrstn */
                    <0 RK_PC3 4 &pcfg_pull_none>;
            };
        };

        pcie20 {
            /omit-if-no-ref/
            pcie20m0_pins: pcie20m0-pins {
                rockchip,pins =
                    /* pcie20_clkreqnm0 */
                    <0 RK_PA5 3 &pcfg_pull_none>,
                    /* pcie20_perstnm0 */
                    <0 RK_PB6 3 &pcfg_pull_none>,
                    /* pcie20_wakenm0 */
                    <0 RK_PB5 3 &pcfg_pull_none>;
            };

            /omit-if-no-ref/
            pcie20m1_pins: pcie20m1-pins {
                rockchip,pins =
                    /* pcie20_clkreqnm1 */
                    <2 RK_PD0 4 &pcfg_pull_none>,
                    /* pcie20_perstnm1 */
                    <3 RK_PC1 4 &pcfg_pull_none>,
                    /* pcie20_wakenm1 */
                    <2 RK_PD1 4 &pcfg_pull_none>;
            };

            /omit-if-no-ref/
            pcie20m2_pins: pcie20m2-pins {
                rockchip,pins =
                    /* pcie20_clkreqnm2 */
                    <1 RK_PB0 4 &pcfg_pull_none>,
                    /* pcie20_perstnm2 */
                    <1 RK_PB2 4 &pcfg_pull_none>,
                    /* pcie20_wakenm2 */
                    <1 RK_PB1 4 &pcfg_pull_none>;
            };

            /omit-if-no-ref/
            pcie20_buttonrstn: pcie20-buttonrstn {
                rockchip,pins =
                    /* pcie20_buttonrstn */
                    <0 RK_PB4 3 &pcfg_pull_none>;
            };
        };

        pcie30x1 {
            /omit-if-no-ref/
            pcie30x1m0_pins: pcie30x1m0-pins {
                rockchip,pins =
                    /* pcie30x1_clkreqnm0 */
                    <0 RK_PA4 3 &pcfg_pull_none>,
                    /* pcie30x1_perstnm0 */
                    <0 RK_PC3 3 &pcfg_pull_none>,
                    /* pcie30x1_wakenm0 */
                    <0 RK_PC2 3 &pcfg_pull_none>;
            };

            /omit-if-no-ref/
            pcie30x1m1_pins: pcie30x1m1-pins {
                rockchip,pins =
                    /* pcie30x1_clkreqnm1 */
                    <2 RK_PD2 4 &pcfg_pull_none>,
                    /* pcie30x1_perstnm1 */
                    <3 RK_PA1 4 &pcfg_pull_none>,
                    /* pcie30x1_wakenm1 */
                    <2 RK_PD3 4 &pcfg_pull_none>;
            };

            /omit-if-no-ref/
            pcie30x1m2_pins: pcie30x1m2-pins {
                rockchip,pins =
                    /* pcie30x1_clkreqnm2 */
                    <1 RK_PA5 4 &pcfg_pull_none>,
                    /* pcie30x1_perstnm2 */
                    <1 RK_PA2 4 &pcfg_pull_none>,
                    /* pcie30x1_wakenm2 */
                    <1 RK_PA3 4 &pcfg_pull_none>;
            };

            /omit-if-no-ref/
            pcie30x1_buttonrstn: pcie30x1-buttonrstn {
                rockchip,pins =
                    /* pcie30x1_buttonrstn */
                    <0 RK_PB3 3 &pcfg_pull_none>;
            };
        };

        pcie30x2 {
            /omit-if-no-ref/
            pcie30x2m0_pins: pcie30x2m0-pins {
                rockchip,pins =
                    /* pcie30x2_clkreqnm0 */
                    <0 RK_PA6 2 &pcfg_pull_none>,
                    /* pcie30x2_perstnm0 */
                    <0 RK_PC6 3 &pcfg_pull_none>,
                    /* pcie30x2_wakenm0 */
                    <0 RK_PC5 3 &pcfg_pull_none>;
            };

            /omit-if-no-ref/
            pcie30x2m1_pins: pcie30x2m1-pins {
                rockchip,pins =
                    /* pcie30x2_clkreqnm1 */
                    <2 RK_PD4 4 &pcfg_pull_none>,
                    /* pcie30x2_perstnm1 */
                    <2 RK_PD6 4 &pcfg_pull_none>,
                    /* pcie30x2_wakenm1 */
                    <2 RK_PD5 4 &pcfg_pull_none>;
            };

            /omit-if-no-ref/
            pcie30x2m2_pins: pcie30x2m2-pins {
                rockchip,pins =
                    /* pcie30x2_clkreqnm2 */
                    <4 RK_PC2 4 &pcfg_pull_none>,
                    /* pcie30x2_perstnm2 */
                    <4 RK_PC4 4 &pcfg_pull_none>,
                    /* pcie30x2_wakenm2 */
                    <4 RK_PC3 4 &pcfg_pull_none>;
            };

            /omit-if-no-ref/
            pcie30x2_buttonrstn: pcie30x2-buttonrstn {
                rockchip,pins =
                    /* pcie30x2_buttonrstn */
                    <0 RK_PB0 3 &pcfg_pull_none>;
            };
        };

        pmic {
            /omit-if-no-ref/
            pmic_pins: pmic-pins {
                rockchip,pins =
                    /* pmic_sleep */
                    <0 RK_PA2 1 &pcfg_pull_none>;
            };
        };

        pmu {
            /omit-if-no-ref/
            pmu_pins: pmu-pins {
                rockchip,pins =
                    /* pmu_debug0 */
                    <0 RK_PA5 4 &pcfg_pull_none>,
                    /* pmu_debug1 */
                    <0 RK_PA6 3 &pcfg_pull_none>,
                    /* pmu_debug2 */
                    <0 RK_PC4 4 &pcfg_pull_none>,
                    /* pmu_debug3 */
                    <0 RK_PC5 4 &pcfg_pull_none>,
                    /* pmu_debug4 */
                    <0 RK_PC6 4 &pcfg_pull_none>,
                    /* pmu_debug5 */
                    <0 RK_PC7 4 &pcfg_pull_none>;
            };
        };

        pwm0 {
            /omit-if-no-ref/
            pwm0m0_pins: pwm0m0-pins {
                rockchip,pins =
                    /* pwm0_m0 */
                    <0 RK_PB7 1 &pcfg_pull_none>;
            };

            /omit-if-no-ref/
            pwm0m1_pins: pwm0m1-pins {
                rockchip,pins =
                    /* pwm0_m1 */
                    <0 RK_PC7 2 &pcfg_pull_none>;
            };
        };

        pwm1 {
            /omit-if-no-ref/
            pwm1m0_pins: pwm1m0-pins {
                rockchip,pins =
                    /* pwm1_m0 */
                    <0 RK_PC0 1 &pcfg_pull_none>;
            };

            /omit-if-no-ref/
            pwm1m1_pins: pwm1m1-pins {
                rockchip,pins =
                    /* pwm1_m1 */
                    <0 RK_PB5 4 &pcfg_pull_none>;
            };
        };

        pwm2 {
            /omit-if-no-ref/
            pwm2m0_pins: pwm2m0-pins {
                rockchip,pins =
                    /* pwm2_m0 */
                    <0 RK_PC1 1 &pcfg_pull_none>;
            };

            /omit-if-no-ref/
            pwm2m1_pins: pwm2m1-pins {
                rockchip,pins =
                    /* pwm2_m1 */
                    <0 RK_PB6 4 &pcfg_pull_none>;
            };
        };

        pwm3 {
            /omit-if-no-ref/
            pwm3_pins: pwm3-pins {
                rockchip,pins =
                    /* pwm3_ir */
                    <0 RK_PC2 1 &pcfg_pull_none>;
            };
        };

        pwm4 {
            /omit-if-no-ref/
            pwm4_pins: pwm4-pins {
                rockchip,pins =
                    /* pwm4 */
                    <0 RK_PC3 1 &pcfg_pull_none>;
            };
        };

        pwm5 {
            /omit-if-no-ref/
            pwm5_pins: pwm5-pins {
                rockchip,pins =
                    /* pwm5 */
                    <0 RK_PC4 1 &pcfg_pull_none>;
            };
        };

        pwm6 {
            /omit-if-no-ref/
            pwm6_pins: pwm6-pins {
                rockchip,pins =
                    /* pwm6 */
                    <0 RK_PC5 1 &pcfg_pull_none>;
            };
        };

        pwm7 {
            /omit-if-no-ref/
            pwm7_pins: pwm7-pins {
                rockchip,pins =
                    /* pwm7_ir */
                    <0 RK_PC6 1 &pcfg_pull_none>;
            };
        };

        pwm8 {
            /omit-if-no-ref/
            pwm8m0_pins: pwm8m0-pins {
                rockchip,pins =
                    /* pwm8_m0 */
                    <3 RK_PB1 5 &pcfg_pull_none>;
            };

            /omit-if-no-ref/
            pwm8m1_pins: pwm8m1-pins {
                rockchip,pins =
                    /* pwm8_m1 */
                    <1 RK_PD5 4 &pcfg_pull_none>;
            };
        };

        pwm9 {
            /omit-if-no-ref/
            pwm9m0_pins: pwm9m0-pins {
                rockchip,pins =
                    /* pwm9_m0 */
                    <3 RK_PB2 5 &pcfg_pull_none>;
            };

            /omit-if-no-ref/
            pwm9m1_pins: pwm9m1-pins {
                rockchip,pins =
                    /* pwm9_m1 */
                    <1 RK_PD6 4 &pcfg_pull_none>;
            };
        };

        pwm10 {
            /omit-if-no-ref/
            pwm10m0_pins: pwm10m0-pins {
                rockchip,pins =
                    /* pwm10_m0 */
                    <3 RK_PB5 5 &pcfg_pull_none>;
            };

            /omit-if-no-ref/
            pwm10m1_pins: pwm10m1-pins {
                rockchip,pins =
                    /* pwm10_m1 */
                    <2 RK_PA1 2 &pcfg_pull_none>;
            };
        };

        pwm11 {
            /omit-if-no-ref/
            pwm11m0_pins: pwm11m0-pins {
                rockchip,pins =
                    /* pwm11_irm0 */
                    <3 RK_PB6 5 &pcfg_pull_none>;
            };

            /omit-if-no-ref/
            pwm11m1_pins: pwm11m1-pins {
                rockchip,pins =
                    /* pwm11_irm1 */
                    <4 RK_PC0 3 &pcfg_pull_none>;
            };
        };

        pwm12 {
            /omit-if-no-ref/
            pwm12m0_pins: pwm12m0-pins {
                rockchip,pins =
                    /* pwm12_m0 */
                    <3 RK_PB7 2 &pcfg_pull_none>;
            };

            /omit-if-no-ref/
            pwm12m1_pins: pwm12m1-pins {
                rockchip,pins =
                    /* pwm12_m1 */
                    <4 RK_PC5 1 &pcfg_pull_none>;
            };
        };

        pwm13 {
            /omit-if-no-ref/
            pwm13m0_pins: pwm13m0-pins {
                rockchip,pins =
                    /* pwm13_m0 */
                    <3 RK_PC0 2 &pcfg_pull_none>;
            };

            /omit-if-no-ref/
            pwm13m1_pins: pwm13m1-pins {
                rockchip,pins =
                    /* pwm13_m1 */
                    <4 RK_PC6 1 &pcfg_pull_none>;
            };
        };

        pwm14 {
            /omit-if-no-ref/
            pwm14m0_pins: pwm14m0-pins {
                rockchip,pins =
                    /* pwm14_m0 */
                    <3 RK_PC4 1 &pcfg_pull_none>;
            };

            /omit-if-no-ref/
            pwm14m1_pins: pwm14m1-pins {
                rockchip,pins =
                    /* pwm14_m1 */
                    <4 RK_PC2 1 &pcfg_pull_none>;
            };
        };

        pwm15 {
            /omit-if-no-ref/
            pwm15m0_pins: pwm15m0-pins {
                rockchip,pins =
                    /* pwm15_irm0 */
                    <3 RK_PC5 1 &pcfg_pull_none>;
            };

            /omit-if-no-ref/
            pwm15m1_pins: pwm15m1-pins {
                rockchip,pins =
                    /* pwm15_irm1 */
                    <4 RK_PC3 1 &pcfg_pull_none>;
            };
        };

        refclk {
            /omit-if-no-ref/
            refclk_pins: refclk-pins {
                rockchip,pins =
                    /* refclk_ou */
                    <0 RK_PA0 1 &pcfg_pull_none>;
            };
        };

        sdmmc0 {
            /omit-if-no-ref/
            sdmmc0_bus4: sdmmc0-bus4 {
                rockchip,pins =
                    /* sdmmc0_d0 */
                    <1 RK_PD5 1 &pcfg_pull_up_drv_level_2>,
                    /* sdmmc0_d1 */
                    <1 RK_PD6 1 &pcfg_pull_up_drv_level_2>,
                    /* sdmmc0_d2 */
                    <1 RK_PD7 1 &pcfg_pull_up_drv_level_2>,
                    /* sdmmc0_d3 */
                    <2 RK_PA0 1 &pcfg_pull_up_drv_level_2>;
            };

            /omit-if-no-ref/
            sdmmc0_clk: sdmmc0-clk {
                rockchip,pins =
                    /* sdmmc0_clk */
                    <2 RK_PA2 1 &pcfg_pull_up_drv_level_2>;
            };

            /omit-if-no-ref/
            sdmmc0_cmd: sdmmc0-cmd {
                rockchip,pins =
                    /* sdmmc0_cmd */
                    <2 RK_PA1 1 &pcfg_pull_up_drv_level_2>;
            };

            /omit-if-no-ref/
            sdmmc0_det: sdmmc0-det {
                rockchip,pins =
                    /* sdmmc0_det */
                    <0 RK_PA4 1 &pcfg_pull_up>;
            };

            /omit-if-no-ref/
            sdmmc0_pwren: sdmmc0-pwren {
                rockchip,pins =
                    /* sdmmc0_pwren */
                    <0 RK_PA5 1 &pcfg_pull_none>;
            };
        };

        sdmmc1 {
            /omit-if-no-ref/
            sdmmc1_bus4: sdmmc1-bus4 {
                rockchip,pins =
                    /* sdmmc1_d0 */
                    <2 RK_PA3 1 &pcfg_pull_up_drv_level_2>,
                    /* sdmmc1_d1 */
                    <2 RK_PA4 1 &pcfg_pull_up_drv_level_2>,
                    /* sdmmc1_d2 */
                    <2 RK_PA5 1 &pcfg_pull_up_drv_level_2>,
                    /* sdmmc1_d3 */
                    <2 RK_PA6 1 &pcfg_pull_up_drv_level_2>;
            };

            /omit-if-no-ref/
            sdmmc1_clk: sdmmc1-clk {
                rockchip,pins =
                    /* sdmmc1_clk */
                    <2 RK_PB0 1 &pcfg_pull_up_drv_level_2>;
            };

            /omit-if-no-ref/
            sdmmc1_cmd: sdmmc1-cmd {
                rockchip,pins =
                    /* sdmmc1_cmd */
                    <2 RK_PA7 1 &pcfg_pull_up_drv_level_2>;
            };

            /omit-if-no-ref/
            sdmmc1_det: sdmmc1-det {
                rockchip,pins =
                    /* sdmmc1_det */
                    <2 RK_PB2 1 &pcfg_pull_up>;
            };

            /omit-if-no-ref/
            sdmmc1_pwren: sdmmc1-pwren {
                rockchip,pins =
                    /* sdmmc1_pwren */
                    <2 RK_PB1 1 &pcfg_pull_none>;
            };
        };

        sdmmc2 {
            /omit-if-no-ref/
            sdmmc2m0_bus4: sdmmc2m0-bus4 {
                rockchip,pins =
                    /* sdmmc2_d0m0 */
                    <3 RK_PC6 3 &pcfg_pull_up_drv_level_2>,
                    /* sdmmc2_d1m0 */
                    <3 RK_PC7 3 &pcfg_pull_up_drv_level_2>,
                    /* sdmmc2_d2m0 */
                    <3 RK_PD0 3 &pcfg_pull_up_drv_level_2>,
                    /* sdmmc2_d3m0 */
                    <3 RK_PD1 3 &pcfg_pull_up_drv_level_2>;
            };

            /omit-if-no-ref/
            sdmmc2m0_clk: sdmmc2m0-clk {
                rockchip,pins =
                    /* sdmmc2_clkm0 */
                    <3 RK_PD3 3 &pcfg_pull_up_drv_level_2>;
            };

            /omit-if-no-ref/
            sdmmc2m0_cmd: sdmmc2m0-cmd {
                rockchip,pins =
                    /* sdmmc2_cmdm0 */
                    <3 RK_PD2 3 &pcfg_pull_up_drv_level_2>;
            };

            /omit-if-no-ref/
            sdmmc2m0_det: sdmmc2m0-det {
                rockchip,pins =
                    /* sdmmc2_detm0 */
                    <3 RK_PD4 3 &pcfg_pull_up>;
            };

            /omit-if-no-ref/
            sdmmc2m0_pwren: sdmmc2m0-pwren {
                rockchip,pins =
                    /* sdmmc2m0_pwren */
                    <3 RK_PD5 3 &pcfg_pull_none>;
            };

            /omit-if-no-ref/
            sdmmc2m1_bus4: sdmmc2m1-bus4 {
                rockchip,pins =
                    /* sdmmc2_d0m1 */
                    <3 RK_PA1 5 &pcfg_pull_up_drv_level_2>,
                    /* sdmmc2_d1m1 */
                    <3 RK_PA2 5 &pcfg_pull_up_drv_level_2>,
                    /* sdmmc2_d2m1 */
                    <3 RK_PA3 5 &pcfg_pull_up_drv_level_2>,
                    /* sdmmc2_d3m1 */
                    <3 RK_PA4 5 &pcfg_pull_up_drv_level_2>;
            };

            /omit-if-no-ref/
            sdmmc2m1_clk: sdmmc2m1-clk {
                rockchip,pins =
                    /* sdmmc2_clkm1 */
                    <3 RK_PA6 5 &pcfg_pull_up_drv_level_2>;
            };

            /omit-if-no-ref/
            sdmmc2m1_cmd: sdmmc2m1-cmd {
                rockchip,pins =
                    /* sdmmc2_cmdm1 */
                    <3 RK_PA5 5 &pcfg_pull_up_drv_level_2>;
            };

            /omit-if-no-ref/
            sdmmc2m1_det: sdmmc2m1-det {
                rockchip,pins =
                    /* sdmmc2_detm1 */
                    <3 RK_PA7 4 &pcfg_pull_up>;
            };

            /omit-if-no-ref/
            sdmmc2m1_pwren: sdmmc2m1-pwren {
                rockchip,pins =
                    /* sdmmc2m1_pwren */
                    <3 RK_PB0 4 &pcfg_pull_none>;
            };
        };

        spdif {
            /omit-if-no-ref/
            spdifm0_tx: spdifm0-tx {
                rockchip,pins =
                    /* spdifm0_tx */
                    <1 RK_PA4 4 &pcfg_pull_none>;
            };

            /omit-if-no-ref/
            spdifm1_tx: spdifm1-tx {
                rockchip,pins =
                    /* spdifm1_tx */
                    <3 RK_PC5 2 &pcfg_pull_none>;
            };

            /omit-if-no-ref/
            spdifm2_tx: spdifm2-tx {
                rockchip,pins =
                    /* spdifm2_tx */
                    <4 RK_PC4 2 &pcfg_pull_none>;
            };
        };

        spi0-hs {
            /omit-if-no-ref/
            spi0m0_pins_hs: spi0m0-pins {
                rockchip,pins =
                    /* spi0_clkm0 */
                    <0 RK_PB5 2 &pcfg_pull_up_drv_level_1>,
                    /* spi0_misom0 */
                    <0 RK_PC5 2 &pcfg_pull_up_drv_level_1>,
                    /* spi0_mosim0 */
                    <0 RK_PB6 2 &pcfg_pull_up_drv_level_1>;
            };

            /omit-if-no-ref/
            spi0m0_cs0_hs: spi0m0-cs0 {
                rockchip,pins =
                    /* spi0_cs0m0 */
                    <0 RK_PC6 2 &pcfg_pull_up_drv_level_1>;
            };

            /omit-if-no-ref/
            spi0m0_cs1_hs: spi0m0-cs1 {
                rockchip,pins =
                    /* spi0_cs1m0 */
                    <0 RK_PC4 2 &pcfg_pull_up_drv_level_1>;
            };

            /omit-if-no-ref/
            spi0m1_pins_hs: spi0m1-pins {
                rockchip,pins =
                    /* spi0_clkm1 */
                    <2 RK_PD3 3 &pcfg_pull_up_drv_level_1>,
                    /* spi0_misom1 */
                    <2 RK_PD0 3 &pcfg_pull_up_drv_level_1>,
                    /* spi0_mosim1 */
                    <2 RK_PD1 3 &pcfg_pull_up_drv_level_1>;
            };

            /omit-if-no-ref/
            spi0m1_cs0_hs: spi0m1-cs0 {
                rockchip,pins =
                    /* spi0_cs0m1 */
                    <2 RK_PD2 3 &pcfg_pull_up_drv_level_1>;
            };
        };

        spi1-hs {
            /omit-if-no-ref/
            spi1m0_pins_hs: spi1m0-pins {
                rockchip,pins =
                    /* spi1_clkm0 */
                    <2 RK_PB5 3 &pcfg_pull_up_drv_level_1>,
                    /* spi1_misom0 */
                    <2 RK_PB6 3 &pcfg_pull_up_drv_level_1>,
                    /* spi1_mosim0 */
                    <2 RK_PB7 4 &pcfg_pull_up_drv_level_1>;
            };

            /omit-if-no-ref/
            spi1m0_cs0_hs: spi1m0-cs0 {
                rockchip,pins =
                    /* spi1_cs0m0 */
                    <2 RK_PC0 4 &pcfg_pull_up_drv_level_1>;
            };

            /omit-if-no-ref/
            spi1m0_cs1_hs: spi1m0-cs1 {
                rockchip,pins =
                    /* spi1_cs1m0 */
                    <2 RK_PC6 3 &pcfg_pull_up_drv_level_1>;
            };

            /omit-if-no-ref/
            spi1m1_pins_hs: spi1m1-pins {
                rockchip,pins =
                    /* spi1_clkm1 */
                    <3 RK_PC3 3 &pcfg_pull_up_drv_level_1>,
                    /* spi1_misom1 */
                    <3 RK_PC2 3 &pcfg_pull_up_drv_level_1>,
                    /* spi1_mosim1 */
                    <3 RK_PC1 3 &pcfg_pull_up_drv_level_1>;
            };

            /omit-if-no-ref/
            spi1m1_cs0_hs: spi1m1-cs0 {
                rockchip,pins =
                    /* spi1_cs0m1 */
                    <3 RK_PA1 3 &pcfg_pull_up_drv_level_1>;
            };
        };

        spi2-hs {
            /omit-if-no-ref/
            spi2m0_pins_hs: spi2m0-pins {
                rockchip,pins =
                    /* spi2_clkm0 */
                    <2 RK_PC1 4 &pcfg_pull_up_drv_level_1>,
                    /* spi2_misom0 */
                    <2 RK_PC2 4 &pcfg_pull_up_drv_level_1>,
                    /* spi2_mosim0 */
                    <2 RK_PC3 4 &pcfg_pull_up_drv_level_1>;
            };

            /omit-if-no-ref/
            spi2m0_cs0_hs: spi2m0-cs0 {
                rockchip,pins =
                    /* spi2_cs0m0 */
                    <2 RK_PC4 4 &pcfg_pull_up_drv_level_1>;
            };

            /omit-if-no-ref/
            spi2m0_cs1_hs: spi2m0-cs1 {
                rockchip,pins =
                    /* spi2_cs1m0 */
                    <2 RK_PC5 4 &pcfg_pull_up_drv_level_1>;
            };

            /omit-if-no-ref/
            spi2m1_pins_hs: spi2m1-pins {
                rockchip,pins =
                    /* spi2_clkm1 */
                    <3 RK_PA0 3 &pcfg_pull_up_drv_level_1>,
                    /* spi2_misom1 */
                    <2 RK_PD7 3 &pcfg_pull_up_drv_level_1>,
                    /* spi2_mosim1 */
                    <2 RK_PD6 3 &pcfg_pull_up_drv_level_1>;
            };

            /omit-if-no-ref/
            spi2m1_cs0_hs: spi2m1-cs0 {
                rockchip,pins =
                    /* spi2_cs0m1 */
                    <2 RK_PD5 3 &pcfg_pull_up_drv_level_1>;
            };

            /omit-if-no-ref/
            spi2m1_cs1_hs: spi2m1-cs1 {
                rockchip,pins =
                    /* spi2_cs1m1 */
                    <2 RK_PD4 3 &pcfg_pull_up_drv_level_1>;
            };
        };

        spi3-hs {
            /omit-if-no-ref/
            spi3m0_pins_hs: spi3m0-pins {
                rockchip,pins =
                    /* spi3_clkm0 */
                    <4 RK_PB3 4 &pcfg_pull_up_drv_level_1>,
                    /* spi3_misom0 */
                    <4 RK_PB0 4 &pcfg_pull_up_drv_level_1>,
                    /* spi3_mosim0 */
                    <4 RK_PB2 4 &pcfg_pull_up_drv_level_1>;
            };

            /omit-if-no-ref/
            spi3m0_cs0_hs: spi3m0-cs0 {
                rockchip,pins =
                    /* spi3_cs0m0 */
                    <4 RK_PA6 4 &pcfg_pull_up_drv_level_1>;
            };

            /omit-if-no-ref/
            spi3m0_cs1_hs: spi3m0-cs1 {
                rockchip,pins =
                    /* spi3_cs1m0 */
                    <4 RK_PA7 4 &pcfg_pull_up_drv_level_1>;
            };

            /omit-if-no-ref/
            spi3m1_pins_hs: spi3m1-pins {
                rockchip,pins =
                    /* spi3_clkm1 */
                    <4 RK_PC2 2 &pcfg_pull_up_drv_level_1>,
                    /* spi3_misom1 */
                    <4 RK_PC5 2 &pcfg_pull_up_drv_level_1>,
                    /* spi3_mosim1 */
                    <4 RK_PC3 2 &pcfg_pull_up_drv_level_1>;
            };

            /omit-if-no-ref/
            spi3m1_cs0_hs: spi3m1-cs0 {
                rockchip,pins =
                    /* spi3_cs0m1 */
                    <4 RK_PC6 2 &pcfg_pull_up_drv_level_1>;
            };

            /omit-if-no-ref/
            spi3m1_cs1_hs: spi3m1-cs1 {
                rockchip,pins =
                    /* spi3_cs1m1 */
                    <4 RK_PD1 2 &pcfg_pull_up_drv_level_1>;
            };
        };

        spi0 {
            /omit-if-no-ref/
            spi0m0_pins: spi0m0-pins {
                rockchip,pins =
                    /* spi0_clkm0 */
                    <0 RK_PB5 2 &pcfg_pull_none>,
                    /* spi0_misom0 */
                    <0 RK_PC5 2 &pcfg_pull_none>,
                    /* spi0_mosim0 */
                    <0 RK_PB6 2 &pcfg_pull_none>;
            };

            /omit-if-no-ref/
            spi0m0_cs0: spi0m0-cs0 {
                rockchip,pins =
                    /* spi0_cs0m0 */
                    <0 RK_PC6 2 &pcfg_pull_none>;
            };

            /omit-if-no-ref/
            spi0m0_cs1: spi0m0-cs1 {
                rockchip,pins =
                    /* spi0_cs1m0 */
                    <0 RK_PC4 2 &pcfg_pull_none>;
            };

            /omit-if-no-ref/
            spi0m1_pins: spi0m1-pins {
                rockchip,pins =
                    /* spi0_clkm1 */
                    <2 RK_PD3 3 &pcfg_pull_none>,
                    /* spi0_misom1 */
                    <2 RK_PD0 3 &pcfg_pull_none>,
                    /* spi0_mosim1 */
                    <2 RK_PD1 3 &pcfg_pull_none>;
            };

            /omit-if-no-ref/
            spi0m1_cs0: spi0m1-cs0 {
                rockchip,pins =
                    /* spi0_cs0m1 */
                    <2 RK_PD2 3 &pcfg_pull_none>;
            };
        };

        spi1 {
            /omit-if-no-ref/
            spi1m0_pins: spi1m0-pins {
                rockchip,pins =
                    /* spi1_clkm0 */
                    <2 RK_PB5 3 &pcfg_pull_none>,
                    /* spi1_misom0 */
                    <2 RK_PB6 3 &pcfg_pull_none>,
                    /* spi1_mosim0 */
                    <2 RK_PB7 4 &pcfg_pull_none>;
            };

            /omit-if-no-ref/
            spi1m0_cs0: spi1m0-cs0 {
                rockchip,pins =
                    /* spi1_cs0m0 */
                    <2 RK_PC0 4 &pcfg_pull_none>;
            };

            /omit-if-no-ref/
            spi1m0_cs1: spi1m0-cs1 {
                rockchip,pins =
                    /* spi1_cs1m0 */
                    <2 RK_PC6 3 &pcfg_pull_none>;
            };

            /omit-if-no-ref/
            spi1m1_pins: spi1m1-pins {
                rockchip,pins =
                    /* spi1_clkm1 */
                    <3 RK_PC3 3 &pcfg_pull_none>,
                    /* spi1_misom1 */
                    <3 RK_PC2 3 &pcfg_pull_none>,
                    /* spi1_mosim1 */
                    <3 RK_PC1 3 &pcfg_pull_none>;
            };

            /omit-if-no-ref/
            spi1m1_cs0: spi1m1-cs0 {
                rockchip,pins =
                    /* spi1_cs0m1 */
                    <3 RK_PA1 3 &pcfg_pull_none>;
            };
        };

        spi2 {
            /omit-if-no-ref/
            spi2m0_pins: spi2m0-pins {
                rockchip,pins =
                    /* spi2_clkm0 */
                    <2 RK_PC1 4 &pcfg_pull_none>,
                    /* spi2_misom0 */
                    <2 RK_PC2 4 &pcfg_pull_none>,
                    /* spi2_mosim0 */
                    <2 RK_PC3 4 &pcfg_pull_none>;
            };

            /omit-if-no-ref/
            spi2m0_cs0: spi2m0-cs0 {
                rockchip,pins =
                    /* spi2_cs0m0 */
                    <2 RK_PC4 4 &pcfg_pull_none>;
            };

            /omit-if-no-ref/
            spi2m0_cs1: spi2m0-cs1 {
                rockchip,pins =
                    /* spi2_cs1m0 */
                    <2 RK_PC5 4 &pcfg_pull_none>;
            };

            /omit-if-no-ref/
            spi2m1_pins: spi2m1-pins {
                rockchip,pins =
                    /* spi2_clkm1 */
                    <3 RK_PA0 3 &pcfg_pull_none>,
                    /* spi2_misom1 */
                    <2 RK_PD7 3 &pcfg_pull_none>,
                    /* spi2_mosim1 */
                    <2 RK_PD6 3 &pcfg_pull_none>;
            };

            /omit-if-no-ref/
            spi2m1_cs0: spi2m1-cs0 {
                rockchip,pins =
                    /* spi2_cs0m1 */
                    <2 RK_PD5 3 &pcfg_pull_none>;
            };

            /omit-if-no-ref/
            spi2m1_cs1: spi2m1-cs1 {
                rockchip,pins =
                    /* spi2_cs1m1 */
                    <2 RK_PD4 3 &pcfg_pull_none>;
            };
        };

        spi3 {
            /omit-if-no-ref/
            spi3m0_pins: spi3m0-pins {
                rockchip,pins =
                    /* spi3_clkm0 */
                    <4 RK_PB3 4 &pcfg_pull_none>,
                    /* spi3_misom0 */
                    <4 RK_PB0 4 &pcfg_pull_none>,
                    /* spi3_mosim0 */
                    <4 RK_PB2 4 &pcfg_pull_none>;
            };

            /omit-if-no-ref/
            spi3m0_cs0: spi3m0-cs0 {
                rockchip,pins =
                    /* spi3_cs0m0 */
                    <4 RK_PA6 4 &pcfg_pull_none>;
            };

            /omit-if-no-ref/
            spi3m0_cs1: spi3m0-cs1 {
                rockchip,pins =
                    /* spi3_cs1m0 */
                    <4 RK_PA7 4 &pcfg_pull_none>;
            };

            /omit-if-no-ref/
            spi3m1_pins: spi3m1-pins {
                rockchip,pins =
                    /* spi3_clkm1 */
                    <4 RK_PC2 2 &pcfg_pull_none>,
                    /* spi3_misom1 */
                    <4 RK_PC5 2 &pcfg_pull_none>,
                    /* spi3_mosim1 */
                    <4 RK_PC3 2 &pcfg_pull_none>;
            };

            /omit-if-no-ref/
            spi3m1_cs0: spi3m1-cs0 {
                rockchip,pins =
                    /* spi3_cs0m1 */
                    <4 RK_PC6 2 &pcfg_pull_none>;
            };

            /omit-if-no-ref/
            spi3m1_cs1: spi3m1-cs1 {
                rockchip,pins =
                    /* spi3_cs1m1 */
                    <4 RK_PD1 2 &pcfg_pull_none>;
            };
        };

        uart0 {
            /omit-if-no-ref/
            uart0_xfer: uart0-xfer {
                rockchip,pins =
                    /* uart0_rx */
                    <0 RK_PC0 3 &pcfg_pull_up>,
                    /* uart0_tx */
                    <0 RK_PC1 3 &pcfg_pull_up>;
            };

            /omit-if-no-ref/
            uart0_ctsn: uart0-ctsn {
                rockchip,pins =
                    /* uart0_ctsn */
                    <0 RK_PC7 3 &pcfg_pull_none>;
            };

            /omit-if-no-ref/
            uart0_rtsn: uart0-rtsn {
                rockchip,pins =
                    /* uart0_rtsn */
                    <0 RK_PC4 3 &pcfg_pull_none>;
            };
        };

        uart1 {
            /omit-if-no-ref/
            uart1m0_xfer: uart1m0-xfer {
                rockchip,pins =
                    /* uart1_rxm0 */
                    <2 RK_PB3 2 &pcfg_pull_up>,
                    /* uart1_txm0 */
                    <2 RK_PB4 2 &pcfg_pull_up>;
            };

            /omit-if-no-ref/
            uart1m0_ctsn: uart1m0-ctsn {
                rockchip,pins =
                    /* uart1m0_ctsn */
                    <2 RK_PB6 2 &pcfg_pull_none>;
            };

            /omit-if-no-ref/
            uart1m0_rtsn: uart1m0-rtsn {
                rockchip,pins =
                    /* uart1m0_rtsn */
                    <2 RK_PB5 2 &pcfg_pull_none>;
            };

            /omit-if-no-ref/
            uart1m1_xfer: uart1m1-xfer {
                rockchip,pins =
                    /* uart1_rxm1 */
                    <3 RK_PD7 4 &pcfg_pull_up>,
                    /* uart1_txm1 */
                    <3 RK_PD6 4 &pcfg_pull_up>;
            };

            /omit-if-no-ref/
            uart1m1_ctsn: uart1m1-ctsn {
                rockchip,pins =
                    /* uart1m1_ctsn */
                    <4 RK_PC1 4 &pcfg_pull_none>;
            };

            /omit-if-no-ref/
            uart1m1_rtsn: uart1m1-rtsn {
                rockchip,pins =
                    /* uart1m1_rtsn */
                    <4 RK_PB6 4 &pcfg_pull_none>;
            };
        };

        uart2 {
            /omit-if-no-ref/
            uart2m0_xfer: uart2m0-xfer {
                rockchip,pins =
                    /* uart2_rxm0 */
                    <0 RK_PD0 1 &pcfg_pull_up>,
                    /* uart2_txm0 */
                    <0 RK_PD1 1 &pcfg_pull_up>;
            };

            /omit-if-no-ref/
            uart2m1_xfer: uart2m1-xfer {
                rockchip,pins =
                    /* uart2_rxm1 */
                    <1 RK_PD6 2 &pcfg_pull_up>,
                    /* uart2_txm1 */
                    <1 RK_PD5 2 &pcfg_pull_up>;
            };
        };

        uart3 {
            /omit-if-no-ref/
            uart3m0_xfer: uart3m0-xfer {
                rockchip,pins =
                    /* uart3_rxm0 */
                    <1 RK_PA0 2 &pcfg_pull_up>,
                    /* uart3_txm0 */
                    <1 RK_PA1 2 &pcfg_pull_up>;
            };

            /omit-if-no-ref/
            uart3m0_ctsn: uart3m0-ctsn {
                rockchip,pins =
                    /* uart3m0_ctsn */
                    <1 RK_PA3 2 &pcfg_pull_none>;
            };

            /omit-if-no-ref/
            uart3m0_rtsn: uart3m0-rtsn {
                rockchip,pins =
                    /* uart3m0_rtsn */
                    <1 RK_PA2 2 &pcfg_pull_none>;
            };

            /omit-if-no-ref/
            uart3m1_xfer: uart3m1-xfer {
                rockchip,pins =
                    /* uart3_rxm1 */
                    <3 RK_PC0 4 &pcfg_pull_up>,
                    /* uart3_txm1 */
                    <3 RK_PB7 4 &pcfg_pull_up>;
            };
        };

        uart4 {
            /omit-if-no-ref/
            uart4m0_xfer: uart4m0-xfer {
                rockchip,pins =
                    /* uart4_rxm0 */
                    <1 RK_PA4 2 &pcfg_pull_up>,
                    /* uart4_txm0 */
                    <1 RK_PA6 2 &pcfg_pull_up>;
            };

            /omit-if-no-ref/
            uart4m0_ctsn: uart4m0-ctsn {
                rockchip,pins =
                    /* uart4m0_ctsn */
                    <1 RK_PA7 2 &pcfg_pull_none>;
            };

            /omit-if-no-ref/
            uart4m0_rtsn: uart4m0-rtsn {
                rockchip,pins =
                    /* uart4m0_rtsn */
                    <1 RK_PA5 2 &pcfg_pull_none>;
            };

            /omit-if-no-ref/
            uart4m1_xfer: uart4m1-xfer {
                rockchip,pins =
                    /* uart4_rxm1 */
                    <3 RK_PB1 4 &pcfg_pull_up>,
                    /* uart4_txm1 */
                    <3 RK_PB2 4 &pcfg_pull_up>;
            };
        };

        uart5 {
            /omit-if-no-ref/
            uart5m0_xfer: uart5m0-xfer {
                rockchip,pins =
                    /* uart5_rxm0 */
                    <2 RK_PA1 3 &pcfg_pull_up>,
                    /* uart5_txm0 */
                    <2 RK_PA2 3 &pcfg_pull_up>;
            };

            /omit-if-no-ref/
            uart5m0_ctsn: uart5m0-ctsn {
                rockchip,pins =
                    /* uart5m0_ctsn */
                    <1 RK_PD7 3 &pcfg_pull_none>;
            };

            /omit-if-no-ref/
            uart5m0_rtsn: uart5m0-rtsn {
                rockchip,pins =
                    /* uart5m0_rtsn */
                    <2 RK_PA0 3 &pcfg_pull_none>;
            };

            /omit-if-no-ref/
            uart5m1_xfer: uart5m1-xfer {
                rockchip,pins =
                    /* uart5_rxm1 */
                    <3 RK_PC3 4 &pcfg_pull_up>,
                    /* uart5_txm1 */
                    <3 RK_PC2 4 &pcfg_pull_up>;
            };
        };

        uart6 {
            /omit-if-no-ref/
            uart6m0_xfer: uart6m0-xfer {
                rockchip,pins =
                    /* uart6_rxm0 */
                    <2 RK_PA3 3 &pcfg_pull_up>,
                    /* uart6_txm0 */
                    <2 RK_PA4 3 &pcfg_pull_up>;
            };

            /omit-if-no-ref/
            uart6m0_ctsn: uart6m0-ctsn {
                rockchip,pins =
                    /* uart6m0_ctsn */
                    <2 RK_PC0 3 &pcfg_pull_none>;
            };

            /omit-if-no-ref/
            uart6m0_rtsn: uart6m0-rtsn {
                rockchip,pins =
                    /* uart6m0_rtsn */
                    <2 RK_PB7 3 &pcfg_pull_none>;
            };

            /omit-if-no-ref/
            uart6m1_xfer: uart6m1-xfer {
                rockchip,pins =
                    /* uart6_rxm1 */
                    <1 RK_PD6 3 &pcfg_pull_up>,
                    /* uart6_txm1 */
                    <1 RK_PD5 3 &pcfg_pull_up>;
            };
        };

        uart7 {
            /omit-if-no-ref/
            uart7m0_xfer: uart7m0-xfer {
                rockchip,pins =
                    /* uart7_rxm0 */
                    <2 RK_PA5 3 &pcfg_pull_up>,
                    /* uart7_txm0 */
                    <2 RK_PA6 3 &pcfg_pull_up>;
            };

            /omit-if-no-ref/
            uart7m0_ctsn: uart7m0-ctsn {
                rockchip,pins =
                    /* uart7m0_ctsn */
                    <2 RK_PC2 3 &pcfg_pull_none>;
            };

            /omit-if-no-ref/
            uart7m0_rtsn: uart7m0-rtsn {
                rockchip,pins =
                    /* uart7m0_rtsn */
                    <2 RK_PC1 3 &pcfg_pull_none>;
            };

            /omit-if-no-ref/
            uart7m1_xfer: uart7m1-xfer {
                rockchip,pins =
                    /* uart7_rxm1 */
                    <3 RK_PC5 4 &pcfg_pull_up>,
                    /* uart7_txm1 */
                    <3 RK_PC4 4 &pcfg_pull_up>;
            };

            /omit-if-no-ref/
            uart7m2_xfer: uart7m2-xfer {
                rockchip,pins =
                    /* uart7_rxm2 */
                    <4 RK_PA3 4 &pcfg_pull_up>,
                    /* uart7_txm2 */
                    <4 RK_PA2 4 &pcfg_pull_up>;
            };
        };

        uart8 {
            /omit-if-no-ref/
            uart8m0_xfer: uart8m0-xfer {
                rockchip,pins =
                    /* uart8_rxm0 */
                    <2 RK_PC6 2 &pcfg_pull_up>,
                    /* uart8_txm0 */
                    <2 RK_PC5 3 &pcfg_pull_up>;
            };

            /omit-if-no-ref/
            uart8m0_ctsn: uart8m0-ctsn {
                rockchip,pins =
                    /* uart8m0_ctsn */
                    <2 RK_PB2 3 &pcfg_pull_none>;
            };

            /omit-if-no-ref/
            uart8m0_rtsn: uart8m0-rtsn {
                rockchip,pins =
                    /* uart8m0_rtsn */
                    <2 RK_PB1 3 &pcfg_pull_none>;
            };

            /omit-if-no-ref/
            uart8m1_xfer: uart8m1-xfer {
                rockchip,pins =
                    /* uart8_rxm1 */
                    <3 RK_PA0 4 &pcfg_pull_up>,
                    /* uart8_txm1 */
                    <2 RK_PD7 4 &pcfg_pull_up>;
            };
        };

        uart9 {
            /omit-if-no-ref/
            uart9m0_xfer: uart9m0-xfer {
                rockchip,pins =
                    /* uart9_rxm0 */
                    <2 RK_PA7 3 &pcfg_pull_up>,
                    /* uart9_txm0 */
                    <2 RK_PB0 3 &pcfg_pull_up>;
            };

            /omit-if-no-ref/
            uart9m0_ctsn: uart9m0-ctsn {
                rockchip,pins =
                    /* uart9m0_ctsn */
                    <2 RK_PC4 3 &pcfg_pull_none>;
            };

            /omit-if-no-ref/
            uart9m0_rtsn: uart9m0-rtsn {
                rockchip,pins =
                    /* uart9m0_rtsn */
                    <2 RK_PC3 3 &pcfg_pull_none>;
            };

            /omit-if-no-ref/
            uart9m1_xfer: uart9m1-xfer {
                rockchip,pins =
                    /* uart9_rxm1 */
                    <4 RK_PC6 4 &pcfg_pull_up>,
                    /* uart9_txm1 */
                    <4 RK_PC5 4 &pcfg_pull_up>;
            };

            /omit-if-no-ref/
            uart9m2_xfer: uart9m2-xfer {
                rockchip,pins =
                    /* uart9_rxm2 */
                    <4 RK_PA5 4 &pcfg_pull_up>,
                    /* uart9_txm2 */
                    <4 RK_PA4 4 &pcfg_pull_up>;
            };
        };

        vop {
            /omit-if-no-ref/
            vopm0_pins: vopm0-pins {
                rockchip,pins =
                    /* vop_pwmm0 */
                    <0 RK_PC3 2 &pcfg_pull_none>;
            };

            /omit-if-no-ref/
            vopm1_pins: vopm1-pins {
                rockchip,pins =
                    /* vop_pwmm1 */
                    <3 RK_PC4 2 &pcfg_pull_none>;
            };
        };
    };
};
